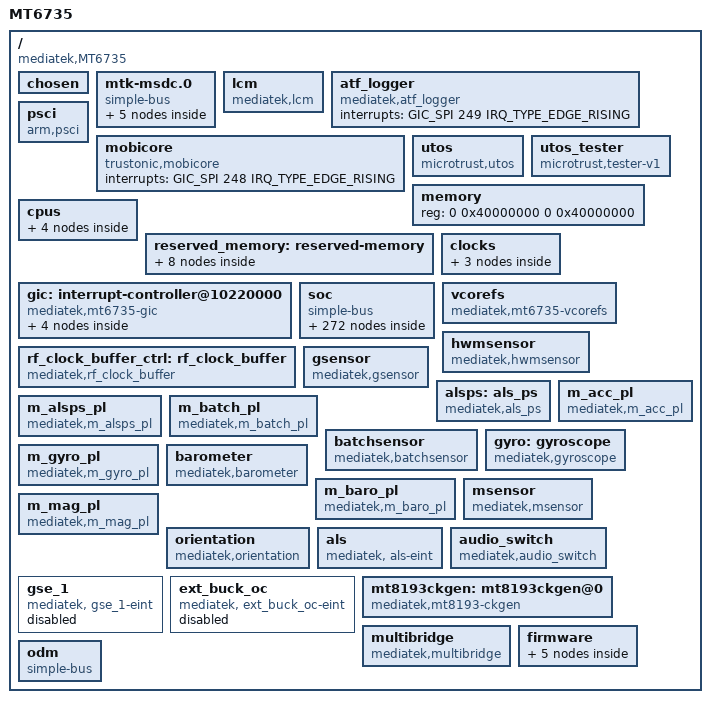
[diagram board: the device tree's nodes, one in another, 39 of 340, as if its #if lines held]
/*
 * Copyright (c) 2015 MediaTek Inc.
 *
 * This program is free software; you can redistribute it and/or modify
 * it under the terms of the GNU General Public License version 2 as
 * published by the Free Software Foundation.
 *
 * This program is distributed in the hope that it will be useful,
 * but WITHOUT ANY WARRANTY; without even the implied warranty of
 * MERCHANTABILITY or FITNESS FOR A PARTICULAR PURPOSE.  See the
 * GNU General Public License for more details.
 */

#include <generated/autoconf.h>
#include <dt-bindings/clock/mt6735-clk.h>
#include <dt-bindings/interrupt-controller/arm-gic.h>
#include <dt-bindings/interrupt-controller/irq.h>
#include "mt6735-pinfunc.h"
#include <dt-bindings/mmc/mt67xx-msdc.h>
#ifdef CONFIG_MTK_DTBO_FEATURE
/dts-v1/;
#endif

/ {
	model = "MT6735";
	compatible = "mediatek,MT6735";
	interrupt-parent = <&gic>;
	#address-cells = <2>;
	#size-cells = <2>;

	/* chosen */
	chosen: chosen {
		bootargs = "console=tty0 console=ttyMT3,921600n1 vmalloc=496M \
androidboot.hardware=mt6735 slub_max_order=0 slub_debug=OFZPU \
firmware_class.path=/vendor/firmware";
	};

	/* Do not put any bus before mtk-msdc, because it should be mtk-msdc.0 for partition device node usage */
	/*workaround for .0*/
	mtk-msdc.0 {
		compatible = "simple-bus";
		#address-cells = <1>;
		#size-cells = <1>;
		ranges = <0 0 0 0xffffffff>;

		mmc0: msdc0@11230000{
				compatible = "mediatek,mt6735-mmc";
				reg = <0x11230000 0x10000  /* MSDC0_BASE   */
					0x10000e84 0x2>;    /* FPGA PWR_GPIO, PWR_GPIO_EO */
				interrupts = <GIC_SPI 79 IRQ_TYPE_LEVEL_LOW>;
				status = "disabled";
				clocks = <&perisys PERI_MSDC30_0>,
					 <&topckgen TOP_MUX_MSDC30_0>,
					 <&topckgen TOP_MSDCPLL_CK>,
					 <&topckgen TOP_MSDCPLL_D2>,
					 <&topckgen TOP_MSDCPLL_D4>;
				clock-names="MSDC0-CLOCK",
					"MSDC0_PLL_SEL",
					"MSDC0_PLL_800M",
					"MSDC0_PLL_400M",
					"MSDC0_PLL_200M";
		};

		mmc1: msdc1@11240000{
				compatible = "mediatek,mt6735-mmc";
				reg = <0x11240000 0x10000  /* MSDC1_BASE   */
					0x10000e84 0x2>;    /* FPGA PWR_GPIO, PWR_GPIO_EO */
				interrupts = <GIC_SPI 80 IRQ_TYPE_LEVEL_LOW>;
				status = "disabled";
				clocks = <&perisys PERI_MSDC30_1>;
				clock-names="MSDC1-CLOCK";
		};

		mmc2: msdc2@11250000{
				compatible = "mediatek,mt6735-mmc";
				reg = <0x11250000 0x10000  /* MSDC2_BASE   */
					0x10000e84 0x2>;    /* FPGA PWR_GPIO, PWR_GPIO_EO */
				interrupts = <GIC_SPI 81 IRQ_TYPE_LEVEL_LOW>;
				status = "disabled";
				clocks = <&perisys PERI_MSDC30_2>;
				clock-names="MSDC2-CLOCK";
		};

		mmc3: msdc3@11260000{
				compatible = "mediatek,mt6735-mmc";
				reg = <0x11260000 0x10000  /* MSDC2_BASE   */
					0x10000e84 0x2>;    /* FPGA PWR_GPIO, PWR_GPIO_EO */
				interrupts = <GIC_SPI 82 IRQ_TYPE_LEVEL_LOW>;
				status = "disabled";
				clocks = <&perisys PERI_MSDC30_3>;
				clock-names="MSDC3-CLOCK";
		};

	/* only used for old way of DCT, can be removed in new platform */
	msdc1_ins: default {
		compatible = "mediatek, msdc1_ins-eint";
	};
	};
	lcm: lcm {
		compatible = "mediatek,lcm";
	};

	/* ATF logger SW IRQ number 281 = 32 + 249 */
	atf_logger {
		compatible = "mediatek,atf_logger";
		interrupts = <GIC_SPI 249 IRQ_TYPE_EDGE_RISING>;
	};

	psci {
		compatible  = "arm,psci";
		method      = "smc";
		cpu_suspend = <0x84000001>;
		cpu_off     = <0x84000002>;
		cpu_on      = <0x84000003>;
		affinity_info = <0x84000004>;
	};

	mobicore {
		compatible = "trustonic,mobicore";
		interrupts = <GIC_SPI 248 IRQ_TYPE_EDGE_RISING>;
	};

	utos {
	compatible = "microtrust,utos";
	interrupts = <GIC_SPI 252 IRQ_TYPE_EDGE_RISING>,
		<GIC_SPI 253 IRQ_TYPE_EDGE_RISING>;
	};
	utos_tester {
		compatible = "microtrust,tester-v1";
	};


	memory {
		device_type = "memory";
		reg = <0 0x40000000 0 0x40000000>;
	};

	cpus: cpus {
		#address-cells = <1>;
		#size-cells = <0>;

		cpu0: cpu@000 {
			device_type = "cpu";
			compatible = "arm,cortex-a53";
			reg = <0x000>;
			enable-method = "spin-table";
			cpu-release-addr = <0x0 0x40000200>;
			clock-frequency = <1300000000>;
		};

		cpu1: cpu@001 {
			device_type = "cpu";
			compatible = "arm,cortex-a53";
			reg = <0x001>;
			enable-method = "spin-table";
			cpu-release-addr = <0x0 0x40000200>;
			clock-frequency = <1300000000>;
		};

		cpu2: cpu@002 {
			device_type = "cpu";
			compatible = "arm,cortex-a53";
			reg = <0x002>;
			enable-method = "spin-table";
			cpu-release-addr = <0x0 0x40000200>;
			clock-frequency = <1300000000>;
		};

		cpu3: cpu@003 {
			device_type = "cpu";
			compatible = "arm,cortex-a53";
			reg = <0x003>;
			enable-method = "spin-table";
			cpu-release-addr = <0x0 0x40000200>;
			clock-frequency = <1300000000>;
		};
	};

	reserved_memory: reserved-memory {
		#address-cells = <2>;
		#size-cells = <2>;
		ranges;

		atf-reserved-memory@43000000 {
			compatible = "mediatek,mt6735-atf-reserved-memory",
				     "mediatek,mt6735m-atf-reserved-memory",
				     "mediatek,mt6753-atf-reserved-memory";
			no-map;
			reg = <0 0x43000000 0 0x30000>;
		};

		ram_console-reserved-memory@43f00000{
			compatible = "mediatek,ram_console";
			reg = <0 0x43f00000 0 0x10000>;
		};

		pstore-reserved-memory@43f10000 {
			compatible = "mediatek,pstore";
			reg = <0 0x43f10000 0 0xe0000>;
		};

		minirdump-reserved-memory@43ff0000{
			compatible = "mediatek,minirdump";
			reg = <0 0x43ff0000 0 0x10000>;
		};

		reserve-memory-ccci_md1 {
			compatible = "mediatek,reserve-memory-ccci_md1";
			no-map;
			size = <0 0x3810000>; /* md_size+smem_size */
			alignment = <0 0x2000000>;
			alloc-ranges = <0 0x40000000 0 0xC0000000>;
		};

		consys-reserve-memory {
			compatible = "mediatek,consys-reserve-memory";
			no-map;
			size = <0 0x100000>;
			alignment = <0 0x200000>;
		};

#ifdef CONFIG_MICROTRUST_TEE_SUPPORT
		soter-shared-mem {
			compatible = "microtrust,shared_mem";
			no-map;
			size = <0 0x200000>;
			alloc-ranges = <0 0x40000000 0 0x50000000>;
		};
#endif

		spm-reserve-memory {
			compatible = "mediatek,spm-reserve-memory";
			no-map;
			size = <0 0x10000>; /* PCM_FIRMWARE_SIZE * DYNA_LOAD_PCM_MAX = 4K * 4 */
			alignment = <0 0x10000>;
			alloc-ranges = <0 0x40000000 0 0x60000000>;
		};
	};

	gic: interrupt-controller@10220000 {
		compatible = "mediatek,mt6735-gic";
		#interrupt-cells = <3>;
		#address-cells = <0>;
		interrupt-controller;
		reg =	<0 0x10221000 0 0x1000>,
			<0 0x10222000 0 0x1000>,
			<0 0x10200620 0 0x1000>;

		mediatek,wdt_irq = <160>;

		gic-cpuif@0 {
			compatible = "arm,gic-cpuif";
			cpuif-id = <0>;
			cpu = <&cpu0>;
		};

		gic-cpuif@1 {
			compatible = "arm,gic-cpuif";
			cpuif-id = <1>;
			cpu = <&cpu1>;
		};

		gic-cpuif@2 {
			compatible = "arm,gic-cpuif";
			cpuif-id = <2>;
			cpu = <&cpu2>;
		};

		gic-cpuif@3 {
			compatible = "arm,gic-cpuif";
			cpuif-id = <3>;
			cpu = <&cpu3>;
		};
	};

	clocks {
		clk_null: clk_null {
			compatible = "fixed-clock";
			#clock-cells = <0>;
			clock-frequency = <0>;
		};

		clk26m: clk26m {
			compatible = "fixed-clock";
			#clock-cells = <0>;
			clock-frequency = <26000000>;
		};

		clk32k: clk32k {
			compatible = "fixed-clock";
			#clock-cells = <0>;
			clock-frequency = <32000>;
		};
	};

	soc: soc {
		compatible = "simple-bus";
		#address-cells = <1>;
		#size-cells = <1>;
		ranges = <0 0 0 0xffffffff>;


		topckgen: topckgen@10210000 {
			compatible = "mediatek,mt6735-topckgen";
			reg = <0x10210000 0x1000>;
			#clock-cells = <1>;
		};


		chipid@08000000 {
			compatible = "mediatek,chipid";
			reg =	<0x08000000 0x0004>,
				<0x08000004 0x0004>,
				<0x08000008 0x0004>,
				<0x0800000C 0x0004>;
		};

		infrasys: infrasys@10000000 {
			compatible = "mediatek,mt6735-infrasys";
			reg = <0x10000000 0x1000>;
			#clock-cells = <1>;
		};

		scpsys: scpsys@10000000 {
			compatible = "mediatek,mt6735-scpsys";
			reg = <0x10000000 0x1000>, <0x10006000 0x1000>;
			#clock-cells = <1>;
		};


		infracfg_ao@10000000 {
			compatible = "mediatek,infracfg_ao";
			reg = <0x10000000 0x1000>;
		};

		usb2jtag: usb2jtag@10000000 {
			compatible = "mediatek,usb2jtag_v1";
			reg = <0x10000000 0x1000>, <0x11210000 0x1000>;
		};

		pwrap@10001000 {
			compatible = "mediatek,PWRAP";
			reg = <0x10001000 0x1000>;
			interrupts = <GIC_SPI 163 IRQ_TYPE_LEVEL_HIGH>;
		};

		perisys: perisys@10002000 {
			compatible = "mediatek,mt6735-perisys";
			reg = <0x10002000 0x1000>;
			#clock-cells = <1>;
		};

		hacc@10008000 {
			compatible = "mediatek,hacc";
			reg = <0x10008000 0x1000>;
			interrupts = <GIC_SPI 174 IRQ_TYPE_LEVEL_LOW>;
		};

		pericfg@10002000 {
			compatible = "mediatek,pericfg";
			reg = <0x10002000 0x1000>;
		};


		keypad: keypad@10003000 {
			compatible = "mediatek,mt6735-keypad";
			reg = <0x10003000 0x1000>;
			interrupts = <GIC_SPI 164 IRQ_TYPE_EDGE_FALLING>;
		};

		apxgpt: apxgpt@10004000 {
			compatible = "mediatek,mt6735-apxgpt";
			reg = <0x10004000 0x1000>;
			interrupts = <GIC_SPI 152 IRQ_TYPE_LEVEL_LOW>;
			clock-frequency = <13000000>;
		};

		eintc: eintc@10005000 {
			compatible = "mediatek,mt-eic";
			reg = <0x10005000 0x1000>;
			interrupts = <GIC_SPI 153 IRQ_TYPE_LEVEL_HIGH>;

			#interrupt-cells = <2>;
			interrupt-controller;

			mediatek,max_eint_num = <213>;
			mediatek,mapping_table_entry = <0>;

			mediatek,debtime_setting_entry = <10>;
			mediatek,debtime_setting_array	= <0 125>,
							<1 250>,
							<2 500>,
							<3 1000>,
							<4 16000>,
							<5 32000>,
							<6 64000>,
							<7 128000>,
							<8 256000>,
							<9 512000>;
		};

		sleep@10006000 {
			compatible = "mediatek,sleep";
			reg = <0x10006000 0x1000>;
			interrupts = <0 165 0x8>,
				     <0 166 0x8>,
				     <0 167 0x8>,
				     <0 168 0x8>;
		};

		mdcldma:mdcldma@1000A000 {
			compatible = "mediatek,mdcldma";
			reg =	<0x1000A000 0x1000>, /*AP_CLDMA_AO*/
				<0x1000B000 0x1000>, /*MD_CLDMA_AO*/
				<0x1021A000 0x1000>, /*AP_CLDMA_PDN*/
				<0x1021B000 0x1000>, /*MD_CLDMA_PDN*/
				<0x1020A000 0x1000>, /*AP_CCIF_BASE*/
				<0x1020B000 0x1000>; /*MD_CCIF_BASE*/
			interrupts =	<GIC_SPI 145 IRQ_TYPE_LEVEL_HIGH>, /*IRQ_CLDMA*/
					<GIC_SPI 140 IRQ_TYPE_LEVEL_LOW>, /*IRQ_CCIF*/
					<GIC_SPI 221 IRQ_TYPE_EDGE_FALLING>; /*IRQ_MDWDT*/
			mediatek,md_id = <0>;
			mediatek,cldma_capability = <6>;
			mediatek,md_smem_size = <0x10000>; /* md share memory size */
			clocks = <&scpsys SCP_SYS_MD1>;
			clock-names = "scp-sys-md1-main";
		};

		mcucfg@10200000 {
			compatible = "mediatek,mcucfg";
			reg = <0x10200000 0x200>;
			interrupts = <GIC_SPI 71 IRQ_TYPE_LEVEL_HIGH>;
		};

		cpuxgpt: cpuxgpt@10200000 {
			compatible = "mediatek,mt6735-cpuxgpt";
			reg = <0x10200000 0x1000>;
			interrupts = <GIC_SPI 64 IRQ_TYPE_LEVEL_HIGH>,
				<GIC_SPI 65 IRQ_TYPE_LEVEL_HIGH>,
				<GIC_SPI 66 IRQ_TYPE_LEVEL_HIGH>,
				<GIC_SPI 67 IRQ_TYPE_LEVEL_HIGH>,
				<GIC_SPI 68 IRQ_TYPE_LEVEL_HIGH>,
				<GIC_SPI 69 IRQ_TYPE_LEVEL_HIGH>,
				<GIC_SPI 70 IRQ_TYPE_LEVEL_HIGH>,
				<GIC_SPI 71 IRQ_TYPE_LEVEL_HIGH>;
		};

		lastpc: lastpc@10200000 {
			compatible = "mediatek,mt6735-mcucfg";
			reg = <0x10200000 0x200>;
			interrupts = <GIC_SPI 71 IRQ_TYPE_LEVEL_HIGH>;
		};

		emi@10203000 {
			compatible = "mediatek,emi";
			reg = <0x10203000 0x1000>;
			interrupts = <GIC_SPI 136 IRQ_TYPE_LEVEL_HIGH>;
		};


		sys_cirq: sys_cirq@10204000 {
			compatible = "mediatek,mt6735-sys_cirq";
			reg = <0x10204000 0x1000>;
			interrupts = <GIC_SPI 231 IRQ_TYPE_LEVEL_LOW>;
			mediatek,cirq_num = <159>;
			mediatek,spi_start_offset = <72>;
		};

		m4u@10205000 {
			cell-index = <0>;
			compatible = "mediatek,m4u";
			reg = <0x10205000 0x1000>;
			interrupts = <GIC_SPI 146 IRQ_TYPE_LEVEL_LOW>;
			clocks = <&infrasys INFRA_M4U>,
				<&mmsys MM_DISP0_SMI_COMMON>,
				<&mmsys MM_DISP0_SMI_LARB0>,
				<&vdecsys VDEC0_VDEC>,
				<&vdecsys VDEC1_LARB>,
				<&imgsys IMG_IMAGE_LARB2_SMI>,
				<&vencsys VENC_VENC>,
				<&vencsys VENC_LARB>,
				<&scpsys SCP_SYS_DIS>,
				<&scpsys SCP_SYS_VDE>,
				<&scpsys SCP_SYS_ISP>,
				<&scpsys SCP_SYS_VEN>;
			clock-names = "infra_m4u",
					"smi_common",
					"m4u_disp0_smi_larb0",
					"m4u_vdec0_vdec",
					"m4u_vdec1_larb",
					"m4u_img_image_larb2_smi",
					"m4u_venc_venc",
					"m4u_venc_larb",
					"mtcmos-dis",
					"mtcmos-vde",
					"mtcmos-isp",
					"mtcmos-ven";
		};

		efusec@10206000 {
			compatible = "mediatek,efusec";
			reg = <0x10206000 0x1000>;
		};

		devapc@10207000 {
			compatible = "mediatek,devapc";
			reg = <0x10207000 0x1000>;
			interrupts = <GIC_SPI 134 IRQ_TYPE_LEVEL_LOW>;
			clocks = <&infrasys INFRA_DEVAPC>;
			clock-names = "devapc-main";
		};

		bus_dbg@10208000 {
			compatible = "mediatek,bus_dbg-v1";
			reg = <0x10208000 0x1000>;
			interrupts = <GIC_SPI 137 IRQ_TYPE_LEVEL_LOW>;
		};

		apmixedsys: apmixedsys@10209000 {
			compatible = "mediatek,mt6735-apmixedsys";
			reg = <0x10209000 0x1000>;
			#clock-cells = <1>;
		};

		apmixed@10209000 {
			compatible = "mediatek,apmixed";
			reg = <0x10209000 0x1000>;
		};

		fhctl@10209f00 {
			compatible = "mediatek,fhctl";
			reg = <0x10209f00 0x100>;
		};

		dramc_nao: dramc_nao@1020e000 {
			compatible = "mediatek,mt6735-dramc_nao";
			reg = <0x1020e000 0x1000>;
		};



		cksys@10210000 {
			compatible = "mediatek,cksys";
			reg = <0x10210000 0x1000>;
		};

		syscfg_pctl_a: syscfg_pctl_a@10211000 {
			compatible = "mediatek,mt6735-pctl-a-syscfg", "syscon";
			reg = <0 10211000 0 1000>;
		};

		pio: pinctrl@10211000 {
			compatible = "mediatek,mt6735-pinctrl";
			reg = <0 10211000 0 1000>;
			mediatek,pctl-regmap = <&syscfg_pctl_a>;
			pins-are-numbered;
			gpio-controller;
			#gpio-cells = <2>;
		};

		gpio_usage_mapping:gpio {
			compatible = "mediatek,gpio_usage_mapping";
		};

		gpio: gpio@10211000 {
			compatible = "mediatek,gpio";
			reg = <0x10211000 0x1000>;
		};

		toprgu: toprgu@10212000 {
			compatible = "mediatek,mt6735-rgu";
			reg = <0x10212000 0x1000>;
			interrupts = <GIC_SPI 128 IRQ_TYPE_EDGE_FALLING>;
		};

		ddrphy: ddrphy@10213000 {
			compatible = "mediatek,mt6735-ddrphy";
			reg = <0x10213000 0x1000>;
		};

		dramc: dramc@10214000 {
			compatible = "mediatek,mt6735-dramc";
			reg = <0x10214000 0x1000>;
			clocks = <&infrasys INFRA_GCE>;
			clock-names = "infra-cqdma";
		};

		gcpu@10216000 {
			compatible = "mediatek,gcpu";
			reg = <0x10216000 0x1000>;
			interrupts = <GIC_SPI 150 IRQ_TYPE_LEVEL_LOW>;
		};

		gce@10217000 {
			compatible = "mediatek,gce";
			reg = <0x10217000 0x1000>;
			interrupts = <GIC_SPI 151 IRQ_TYPE_LEVEL_LOW>,
						<GIC_SPI 148 IRQ_TYPE_LEVEL_LOW>;
			disp_mutex_reg = <0x14014000 0x1000>;
			g3d_config_base = <0x13000000 0 0xffff0000>;
			mmsys_config_base = <0x14000000 1 0xffff0000>;
			disp_dither_base = <0x14010000 2 0xffff0000>;
			mm_na_base = <0x14020000 3 0xffff0000>;
			imgsys_base = <0x15000000 4 0xffff0000>;
			vdec_gcon_base = <0x16000000 5 0xffff0000>;
			venc_gcon_base = <0x17000000 6 0xffff0000>;
			conn_peri_base = <0x18000000 7 0xffff0000>;
			topckgen_base = <0x10000000 8 0xffff0000>;
			kp_base = <0x10010000 9 0xffff0000>;
			scp_sram_base = <0x10020000 10 0xffff0000>;
			infra_na3_base = <0x10030000 11 0xffff0000>;
			infra_na4_base = <0x10040000 12 0xffff0000>;
			scp_base = <0x10050000 13 0xffff0000>;
			mcucfg_base = <0x10200000 14 0xffff0000>;
			gcpu_base = <0x10210000 15 0xffff0000>;
			usb0_base = <0x11200000 16 0xffff0000>;
			usb_sif_base = <0x11210000 17 0xffff0000>;
			audio_base = <0x11220000 18 0xffff0000>;
			msdc0_base = <0x11230000 19 0xffff0000>;
			msdc1_base = <0x11240000 20 0xffff0000>;
			msdc2_base = <0x11250000 21 0xffff0000>;
			msdc3_base = <0x11260000 22 0xffff0000>;
			pwm_sw_base = <0x1100E000 99 0xfffff000>;
			mdp_rdma0_sof = <0>;
			mdp_rsz0_sof = <1>;
			mdp_rsz1_sof = <2>;
			dsi0_te_event = <3>;
			mdp_wdma_sof = <4>;
			mdp_wrot_sof = <5>;
			disp_ovl0_sof = <6>;
			disp_rdma0_sof = <7>;
			disp_rdma1_sof = <8>;
			disp_wdma0_sof = <9>;
			disp_ccorr_sof = <10>;
			disp_color_sof = <11>;
			disp_aal_sof = <12>;
			disp_gamma_sof = <13>;
			disp_dither_sof = <14>;
			disp_pwm0_sof = <16>;
			mdp_rdma0_frame_done = <17>;
			mdp_rsz0_frame_done = <18>;
			mdp_rsz1_frame_done = <19>;
			mdp_tdshp_frame_done = <20>;
			mdp_wdma_frame_done = <21>;
			mdp_wrot_write_frame_done = <22>;
			mdp_wrot_read_frame_done = <23>;
			disp_ovl0_frame_done = <24>;
			disp_rdma0_frame_done = <25>;
			disp_rdma1_frame_done = <26>;
			disp_wdma0_frame_done = <27>;
			disp_ccorr_frame_done = <28>;
			disp_color_frame_done = <29>;
			disp_aal_frame_done = <30>;
			disp_gamma_frame_done = <31>;
			disp_dither_frame_done = <32>;
			disp_dpi0_frame_done = <34>;
			stream_done_0 = <35>;
			stream_done_1 = <36>;
			stream_done_2 = <37>;
			stream_done_3 = <38>;
			stream_done_4 = <39>;
			stream_done_5 = <40>;
			stream_done_6 = <41>;
			stream_done_7 = <42>;
			stream_done_8 = <43>;
			stream_done_9 = <44>;
			buf_underrun_event_0 = <45>;
			buf_underrun_event_1 = <46>;
			mdp_tdshp_sof = <47>;
			isp_frame_done_p2_2 = <65>;
			isp_frame_done_p2_1 = <66>;
			isp_frame_done_p2_0 = <67>;
			isp_frame_done_p1_1 = <68>;
			isp_frame_done_p1_0 = <69>;
			camsv_2_pass1_done = <70>;
			camsv_1_pass1_done = <71>;
			seninf_cam1_2_3_fifo_full = <72>;
			seninf_cam0_fifo_full = <73>;
			venc_done = <129>;
			jpgenc_done = <130>;
			jpgdec_done = <131>;
			venc_mb_done = <132>;
			venc_128byte_cnt_done = <133>;
			apxgpt2_count = <0x10004028>;
			clocks = <&infrasys INFRA_GCE>;
			clock-names = "GCE";
		};

		cqdma@10217c00 {
			compatible = "mediatek,cqdma";
			reg = <0x10217c00 0xc00>;
			interrupts = <GIC_SPI 151 IRQ_TYPE_LEVEL_LOW>;
			nr_channel = <1>;
		};

		mcu_biu: mcu_biu@10300000 {
			compatible = "mediatek,mt6735-mcu_biu";
			reg = <0x10300000 0x8000>;
		};

		cpu_dbgapb: cpu_dbgapb@10810000 {
			compatible = "mediatek,hw_dbg";
			num = <4>;
			reg =  <0x10810000 0x1000
				0x10910000 0x1000
				0x10a10000 0x1000
				0x10b10000 0x1000>;
		};

		auxadc: adc_hw@11001000 {
			compatible = "mediatek,mt6735-auxadc";
			reg = <0x11001000 0x1000>;
			interrupts = <GIC_SPI 76 IRQ_TYPE_EDGE_FALLING>;
			clocks = <&perisys PERI_AUXADC>;
			clock-names = "auxadc-main";
		};

		dbgapb_base@1011a000{
			compatible = "mediatek,dbgapb_base";
			reg = <0x1011a000 0x100>;/* MD debug register */
		};

		ap_dma:dma@11000000 {
			compatible = "mediatek,ap_dma";
			reg = <0x11000000 0x1000>;
			interrupts = <GIC_SPI 114 IRQ_TYPE_LEVEL_LOW>;
		};

		btif_tx: btif_tx@11000880 {
			compatible = "mediatek,btif_tx";
			reg = <0x11000880 0x80>;
			interrupts = <GIC_SPI 113 IRQ_TYPE_LEVEL_LOW>;
		};

		btif_rx: btif_rx@11000900 {
			compatible = "mediatek,btif_rx";
			reg = <0x11000900 0x80>;
			interrupts = <GIC_SPI 114 IRQ_TYPE_LEVEL_LOW>;
		};

		apirtx:irtx@11011000 {
			compatible = "mediatek,irtx";
			reg = <0x11011000 0x1000>;
			interrupts = <GIC_SPI 124 IRQ_TYPE_LEVEL_HIGH>;
			pwm_ch = <0>;

			clock-frequency = <26000000>;
			clock-div = <1>;
			clocks = <&perisys PERI_IRTX>;
			clock-names = "clk-irtx-main";

			pinctrl-names = "irtx_gpio_default",
					"irtx_gpio_led_set";

			pinctrl-0 = <&irtx_gpio_default>;
			pinctrl-1 = <&irtx_gpio_led_set>;
			status = "okay";
		};

		irtx-pwm {
			compatible = "mediatek,irtx-pwm";
			pwm_ch = <2>;
			pwm_data_invert = <0>;
		};

		irlearning:irlearning-spi {
			compatible = "mediatek,irlearning-spi";
			spi_clock = <109000000>;
			spi_data_invert = <0>;
			spi_cs_invert = <1>;
		};

		apuart0: apuart0@11002000 {
			cell-index = <0>;
			compatible = "mediatek,mt6735-uart";
			reg =	<0x11002000 0x1000>, /* UART base */
				<0x11000380 0x1000>, /* DMA Tx base */
				<0x11000400 0x80>; /* DMA Rx base */
			interrupts =	<GIC_SPI 91 IRQ_TYPE_LEVEL_LOW>, /* UART IRQ */
					<GIC_SPI 103 IRQ_TYPE_LEVEL_LOW>, /* DMA Tx IRQ */
					<GIC_SPI 104 IRQ_TYPE_LEVEL_LOW>; /* DMA Rx IRQ */

			clock-frequency = <26000000>;
			clock-div = <1>;
			clocks = <&perisys PERI_UART0>, <&perisys PERI_APDMA>;
			clock-names = "uart0-main", "uart-apdma";

			pinctrl-names = "uart0_gpio_default",
					"uart0_rx_set",
					"uart0_rx_clear",
					"uart0_tx_set",
					"uart0_tx_clear";

			pinctrl-0 = <&uart0_gpio_def_cfg>;
			pinctrl-1 = <&uart0_rx_set_cfg>;
			pinctrl-2 = <&uart0_rx_clr_cfg>;
			pinctrl-3 = <&uart0_tx_set_cfg>;
			pinctrl-4 = <&uart0_tx_clr_cfg>;
			status = "okay";
		};

		apuart1: apuart1@11003000 {
			cell-index = <1>;
			compatible = "mediatek,mt6735-uart";
			reg =	<0x11003000 0x1000>, /* UART base */
				<0x11000480 0x80>, /* DMA Tx base */
				<0x11000500 0x80>; /* DMA Rx base */
			interrupts = <GIC_SPI 92 IRQ_TYPE_LEVEL_LOW>, /* UART IRQ */
						 <GIC_SPI 105 IRQ_TYPE_LEVEL_LOW>, /* DMA Tx IRQ */
						 <GIC_SPI 106 IRQ_TYPE_LEVEL_LOW>; /* DMA Rx IRQ */

			clock-frequency = <26000000>;
			clock-div = <1>;
			clocks = <&perisys PERI_UART1>;
			clock-names = "uart1-main";

			pinctrl-names = "uart1_gpio_default",
					"uart1_rx_set",
					"uart1_rx_clear",
					"uart1_tx_set",
					"uart1_tx_clear";

			pinctrl-0 = <&uart1_gpio_def_cfg>;
			pinctrl-1 = <&uart1_rx_set_cfg>;
			pinctrl-2 = <&uart1_rx_clr_cfg>;
			pinctrl-3 = <&uart1_tx_set_cfg>;
			pinctrl-4 = <&uart1_tx_clr_cfg>;
			status = "okay";
		};

		apuart2: apuart2@11004000 {
			cell-index = <2>;
			compatible = "mediatek,mt6735-uart";
			reg =	<0x11004000 0x1000>, /* UART base */
				<0x11000580 0x80>, /* DMA Tx base */
				<0x11000600 0x80>; /* DMA Rx base */
			interrupts = <GIC_SPI 93 IRQ_TYPE_LEVEL_LOW>, /* UART IRQ */
						 <GIC_SPI 107 IRQ_TYPE_LEVEL_LOW>, /* DMA Tx IRQ */
						 <GIC_SPI 108 IRQ_TYPE_LEVEL_LOW>; /* DMA Rx IRQ */

			clock-frequency = <26000000>;
			clock-div = <1>;
			clocks = <&perisys PERI_UART2>;
			clock-names = "uart2-main";

			pinctrl-names = "uart2_gpio_default",
					"uart2_rx_set",
					"uart2_rx_clear",
					"uart2_tx_set",
					"uart2_tx_clear";

			pinctrl-0 = <&uart2_gpio_def_cfg>;
			pinctrl-1 = <&uart2_rx_set_cfg>;
			pinctrl-2 = <&uart2_rx_clr_cfg>;
			pinctrl-3 = <&uart2_tx_set_cfg>;
			pinctrl-4 = <&uart2_tx_clr_cfg>;
			status = "okay";
		};

		apuart3: apuart3@11005000 {
			cell-index = <3>;
			compatible = "mediatek,mt6735-uart";
			reg =	<0x11005000 0x1000>, /* UART base */
				<0x11000680 0x80>, /* DMA Tx base */
				<0x11000700 0x80>; /* DMA Rx base */
			interrupts = <GIC_SPI 94 IRQ_TYPE_LEVEL_LOW>, /* UART IRQ */
						 <GIC_SPI 109 IRQ_TYPE_LEVEL_LOW>, /* DMA Tx IRQ */
						 <GIC_SPI 110 IRQ_TYPE_LEVEL_LOW>; /* DMA Rx IRQ */

			clock-frequency = <26000000>;
			clock-div = <1>;
			clocks = <&perisys PERI_UART3>;
			clock-names = "uart3-main";

			pinctrl-names = "uart3_gpio_default",
					"uart3_rx_set",
					"uart3_rx_clear",
					"uart3_tx_set",
					"uart3_tx_clear";

			pinctrl-0 = <&uart3_gpio_def_cfg>;
			pinctrl-1 = <&uart3_rx_set_cfg>;
			pinctrl-2 = <&uart3_rx_clr_cfg>;
			pinctrl-3 = <&uart3_tx_set_cfg>;
			pinctrl-4 = <&uart3_tx_clr_cfg>;
			status = "okay";
		};

		pwm:pwm@11006000 {
			compatible = "mediatek,pwm";
			reg = <0x11006000 0x1000>;
			interrupts = <GIC_SPI 77 IRQ_TYPE_LEVEL_LOW>;
			clocks = <&perisys PERI_PWM>,
					 <&perisys PERI_PWM1>,
					 <&perisys PERI_PWM2>,
					 <&perisys PERI_PWM3>,
					 <&perisys PERI_PWM4>,
					 <&perisys PERI_PWM5>;
			clock-names =	"PWM-main",
					"PWM1-main",
					"PWM2-main",
					"PWM3-main",
					"PWM4-main",
					"PWM5-main";
		};

		devapc_ao@10007000 {
			compatible = "mediatek,devapc_ao";
			reg = <0x10007000 0x1000>;
		};

		i2c0:i2c@11007000 {
			compatible = "mediatek,mt6735-i2c";
			cell-index = <0>;
			reg = <0x11007000 0x1000>;
			interrupts =	<GIC_SPI 84 IRQ_TYPE_LEVEL_LOW>,
					<GIC_SPI 99 IRQ_TYPE_LEVEL_LOW>;
			def_speed = <100>;
			clocks = <&perisys PERI_I2C0>, <&perisys PERI_APDMA>;
			clock-names = "i2c0-main", "i2c0-dma";
			clock-frequency = <13600>;
			clock-div = <1>;
		};

		i2c1:i2c@11008000 {
			compatible = "mediatek,mt6735-i2c";
			cell-index = <1>;
			reg = <0x11008000 0x1000>;
			interrupts =	<GIC_SPI 85 IRQ_TYPE_LEVEL_LOW>,
					<GIC_SPI 100 IRQ_TYPE_LEVEL_LOW>;
			def_speed = <100>;
			clocks = <&perisys PERI_I2C1>, <&perisys PERI_APDMA>;
			clock-names = "i2c1-main", "i2c1-dma";
			clock-frequency = <13600>;
			clock-div = <1>;
		};
		spi0:spi@1100a000 {
			compatible = "mediatek,mt6735-spi";
			cell-index = <0>;
			spi-padmacro = <0>;
			reg = <0x1100a000 0x1000>;
			interrupts = <GIC_SPI 118 IRQ_TYPE_LEVEL_LOW>;
			clocks = <&perisys PERI_SPI0>;
			clock-names = "spi-main";
			clock-frequency = <109000000>;
			clock-div = <1>;
		};

		i2c2:i2c@11009000 {
			compatible = "mediatek,mt6735-i2c";
			cell-index = <2>;
			reg = <0x11009000 0x1000>;
			interrupts =	<GIC_SPI 86 IRQ_TYPE_LEVEL_LOW>,
					<GIC_SPI 101 IRQ_TYPE_LEVEL_LOW>;
			def_speed = <100>;
			clocks = <&perisys PERI_I2C2>, <&perisys PERI_APDMA>;
			clock-names = "i2c2-main", "i2c2-dma";
			clock-frequency = <13600>;
			clock-div = <1>;
		};

		therm_ctrl@1100b000 {
			compatible = "mediatek,mt6735-therm_ctrl";
			reg = <0x1100b000 0x1000>;
			interrupts = <GIC_SPI 78 IRQ_TYPE_LEVEL_LOW>;
			clocks = <&perisys PERI_THERM>;
			clock-names = "therm-main";
		};


		ptp_fsm@1100b000 {
			compatible = "mediatek,ptp_fsm_v1";
			reg = <0x1100b000 0x1000>;
			interrupts = <GIC_SPI 125 IRQ_TYPE_LEVEL_LOW>;
		};

		btif: btif@1100c000 {
			compatible = "mediatek,btif";
			reg = <0x1100c000 0x1000>;
			interrupts = <GIC_SPI 90 IRQ_TYPE_LEVEL_LOW>;
			clocks = <&perisys PERI_BTIF>,<&perisys PERI_APDMA>;
			clock-names = "btifc","apdmac";
		};/* End of btif */

		apuart4: apuart4@1100D000 {
			cell-index = <4>;
			compatible = "mediatek,mt6735-uart";
			reg =	<0x1100d000 0x1000>, /* UART base */
				<0x11000780 0x80>, /* DMA Tx base */
				<0x11000800 0x80>; /* DMA Rx base */
			interrupts =	<GIC_SPI 95 IRQ_TYPE_LEVEL_LOW>, /* UART IRQ */
					<GIC_SPI 111 IRQ_TYPE_LEVEL_LOW>, /* DMA Tx IRQ */
					<GIC_SPI 112 IRQ_TYPE_LEVEL_LOW>; /* DMA Rx IRQ */

			clock-frequency = <26000000>;
			clock-div = <1>;
			clocks = <&perisys PERI_UART4>;
			clock-names = "uart4-main";
		};

		i2c3:i2c@1100f000 {
			compatible = "mediatek,mt6735-i2c";
			cell-index = <3>;
			reg = <0x1100f000 0x1000>;
			interrupts =	<GIC_SPI 87 IRQ_TYPE_LEVEL_LOW>,
					<GIC_SPI 102 IRQ_TYPE_LEVEL_LOW>;
			def_speed = <100>;
			clocks = <&perisys PERI_I2C3>, <&perisys PERI_APDMA>;
			clock-names = "i2c3-main", "i2c3-dma";
			clock-frequency = <13600>;
			clock-div = <1>;
		};

		i2c4:i2c@11010000 {
			compatible = "mediatek,mt6735-i2c";
			cell-index = <4>;
			reg = <11010000 0x1000>;
			def_speed = <100>;
			clocks = <&perisys PERI_I2C3>, <&perisys PERI_APDMA>;
			clock-names = "i2c4-main", "i2c4-dma";
			clock-frequency = <13600>;
			clock-div = <1>;
		};

		usb0:usb20@11200000 {
			compatible = "mediatek,mt6735-usb20";
			cell-index = <0>;
			reg = <0x11200000 0x10000>,
			      <0x11210000 0x10000>;
			interrupts = <GIC_SPI 72 IRQ_TYPE_LEVEL_LOW>;
			mode = <2>;
			multipoint = <1>;
			num_eps = <16>;
			clocks = <&perisys PERI_USB0>;
			clock-names = "usb0";
			vusb33-supply = <&mt_pmic_vusb33_ldo_reg>;
			iddig_gpio = <0 1>;
			drvvbus_gpio = <83 2>;
		};

		audiosys: audiosys@11220000 {
			compatible = "mediatek,mt6735-audiosys";
			reg = <0x11220000 0x10000>;
			#clock-cells = <1>;
		};

		audio@11220000 {
			compatible = "mediatek,audio";
			reg = <0x11220000 0x10000>;
			interrupts = <GIC_SPI 144 IRQ_TYPE_LEVEL_LOW>;
		};


		audgpio:mt_soc_dl1_pcm@11220000 {
			compatible = "mediatek,mt-soc-dl1-pcm";
			reg = <0x11220000 0x1000>;
			interrupts = <GIC_SPI 144 IRQ_TYPE_LEVEL_LOW>;
			clocks = <&audiosys AUDIO_AFE>,
				<&audiosys AUDIO_I2S>,
				<&audiosys AUDIO_DAC>,
				<&audiosys AUDIO_DAC_PREDIS>,
				<&audiosys AUDIO_ADC>,
				<&audiosys AUDIO_22M>,
				<&audiosys AUDIO_24M>,
				<&audiosys AUDIO_APLL_TUNER>,
				<&audiosys AUDIO_APLL2_TUNER>,
				<&audiosys AUDIO_TML>,
				<&infrasys INFRA_AUDIO>,
				<&topckgen TOP_MUX_AUD1>,
				<&topckgen TOP_MUX_AUD2>,
				<&topckgen TOP_AD_APLL1_CK>,
				<&topckgen TOP_WHPLL_AUDIO_CK>,
				<&topckgen TOP_MUX_AUDIO>,
				<&topckgen TOP_MUX_AUDINTBUS>,
				<&topckgen TOP_SYSPLL1_D4>,
				<&apmixedsys APMIXED_APLL1>,
				<&apmixedsys APMIXED_APLL2>,
				<&clk26m>;
			clock-names = "aud_afe_clk",
				"aud_i2s_clk",
				"aud_dac_clk",
				"aud_dac_predis_clk",
				"aud_adc_clk",
				"aud_apll22m_clk",
				"aud_apll24m_clk",
				"aud_apll1_tuner_clk",
				"aud_apll2_tuner_clk",
				"aud_tml_clk",
				"aud_infra_clk",
				"aud_mux1_clk",
				"aud_mux2_clk",
				"top_ad_apll1_clk",
				"top_whpll_audio_clk",
				"top_mux_audio",
				"top_mux_audio_int",
				"top_sys_pll1_d4",
				"apmixed_apll1_clk",
				"apmixed_apll2_clk",
				"top_clk26m_clk";
			audclk-gpio = <143 0>;
			audmiso-gpio = <144 0>;
			audmosi-gpio = <145 0>;
			vowclk-gpio = <148 0>;
			extspkamp-gpio = <117 0>;
			i2s1clk-gpio = <80 0>;
			i2s1dat-gpio = <78 0>;
			i2s1mclk-gpio = <9 0>;
			i2s1ws-gpio = <79 0>;
		};


		mfgsys: mfgsys@13000000 {
			compatible = "mediatek,mt6735-mfgsys";
			reg = <0x13000000 0x1000>;
			#clock-cells = <1>;
		};

		g3d_config@13000000 {
			compatible = "mediatek,G3D_CONFIG";
			reg = <0x13000000 0x1000>;
		};

		mali@13040000 {
			compatible = "arm,malit720", "arm,mali-t72x", "arm,malit7xx", "arm,mali-midgard";
			reg = <0x13040000 0x4000>;
			interrupts = <GIC_SPI 212 IRQ_TYPE_LEVEL_LOW>,
				<GIC_SPI 211 IRQ_TYPE_LEVEL_LOW>,
				<GIC_SPI 210 IRQ_TYPE_LEVEL_LOW>;
			interrupt-names = "JOB", "MMU", "GPU";
			clock-frequency = <450000000>;
			clocks = <&mfgsys MFG_BG3D>,
				<&mmsys MM_DISP0_SMI_COMMON>,
				<&scpsys SCP_SYS_MFG>,
				<&scpsys SCP_SYS_DIS>;
			clock-names = "mfg-main", "mfg-smi-common", "mtcmos-mfg", "mtcmos-display";
		};

		mmsys: mmsys@14000000 {
			compatible = "mediatek,mt6735-mmsys";
			reg = <0x14000000 0x1000>;
			#clock-cells = <1>;
		};

		mmsys_config@14000000 {
			compatible = "mediatek,mmsys_config";
			reg = <0x14000000 0x1000>;
			interrupts = <GIC_SPI 205 IRQ_TYPE_LEVEL_LOW>;
			clocks = <&mmsys MM_DISP0_CAM_MDP>;
			clock-names = "CAM_MDP";
		};

		mdp_rdma@14001000 {
			compatible = "mediatek,mdp_rdma";
			reg = <0x14001000 0x1000>;
			interrupts = <GIC_SPI 187 IRQ_TYPE_LEVEL_LOW>;
			clocks = <&mmsys MM_DISP0_MDP_RDMA>;
			clock-names = "MDP_RDMA";
		};

		mdp_rsz0@14002000 {
			compatible = "mediatek,mdp_rsz0";
			reg = <0x14002000 0x1000>;
			interrupts = <GIC_SPI 188 IRQ_TYPE_LEVEL_LOW>;
			clocks = <&mmsys MM_DISP0_MDP_RSZ0>;
			clock-names = "MDP_RSZ0";
		};

		mdp_rsz1@14003000 {
			compatible = "mediatek,mdp_rsz1";
			reg = <0x14003000 0x1000>;
			interrupts = <GIC_SPI 189 IRQ_TYPE_LEVEL_LOW>;
			clocks = <&mmsys MM_DISP0_MDP_RSZ1>;
			clock-names = "MDP_RSZ1";
		};

		mdp_wdma@14004000 {
			compatible = "mediatek,mdp_wdma";
			reg = <0x14004000 0x1000>;
			interrupts = <GIC_SPI 191 IRQ_TYPE_LEVEL_LOW>;
			clocks = <&mmsys MM_DISP0_MDP_WDMA>;
			clock-names = "MDP_WDMA";
		};

		mdp_wrot@14005000 {
			compatible = "mediatek,mdp_wrot";
			reg = <0x14005000 0x1000>;
			interrupts = <GIC_SPI 192 IRQ_TYPE_LEVEL_LOW>;
			clocks = <&mmsys MM_DISP0_MDP_WROT>;
			clock-names = "MDP_WROT";
		};

		mdp_tdshp@14006000 {
			compatible = "mediatek,mdp_tdshp";
			reg = <0x14006000 0x1000>;
			interrupts = <GIC_SPI 190 IRQ_TYPE_LEVEL_LOW>;
			clocks = <&mmsys MM_DISP0_MDP_TDSHP>;
			clock-names = "MDP_TDSHP";
		};

		dpi@14012000 {
			compatible = "mediatek,mt6735-dpi";
			reg = <0x14012000 0x1000>;
			interrupts = <GIC_SPI 204 IRQ_TYPE_LEVEL_LOW>;
		};

		dispsys: dispsys@14007000 {
			compatible = "mediatek,mt6735-dispsys";

			reg = <0x14007000 0x1000>,  /*DISP_OVL0      */
			      <0 0>,		    /*DISP_OVL1      */
			      <0x14008000 0x1000>,  /*DISP_RDMA0     */
			      <0x14009000 0x1000>,  /*DISP_RDMA1     */
			      <0x1400A000 0x1000>,  /*DISP_WDMA0     */
			      <0x1400B000 0x1000>,  /*DISP_COLOR     */
			      <0x1400C000 0x1000>,  /*DISP_CCORR     */
			      <0x1400D000 0x1000>,  /*DISP_AAL       */
			      <0x1400E000 0x1000>,  /*DISP_GAMMA     */
			      <0x1400F000 0x1000>,  /*DISP_DITHER    */
			      <0 0>,		    /*DISP_UFOE      */
			      <0x1100E000 0x1000>,  /*DISP_PWM       */
			      <0 0>,		    /*DISP_WDMA1     */
			      <0x14014000 0x1000>,  /*DISP_MUTEX     */
			      <0x14011000 0x1000>,  /*DISP_DSI0      */
			      <0x14012000 0x1000>,  /*DISP_DPI0      */
			      <0x14000000 0x1000>,  /*DISP_CONFIG    */
			      <0x14015000 0x1000>,  /*DISP_SMI_LARB0 */
			      <0x14016000 0x1000>,  /*DISP_SMI_COMMOM*/
			      <0x14017000 0x1000>,  /*MIPITX0,real chip would use this:<0x14017000 0x1000>;*/
			      <0x10206000 0x1000>,  /*DISP_CONFIG2*/
			      <0x10210000 0x1000>,  /*DISP_CONFIG3*/
			      <0x10211A70 0x000C>,  /*DISP_DPI_IO_DRIVING1 */
			      <0x10211974 0x000C>,  /*DISP_DPI_IO_DRIVING2 */
			      <0x10211B70 0x000C>,  /*DISP_DPI_IO_DRIVING3 */
			      <0x10206044 0x000C>,  /*DISP_DPI_EFUSE */
			      <0x10206514 0x000C>,  /*DISP_DPI_EFUSE_PERMISSION */
			      <0x10206558 0x000C>,  /*DISP_DPI_EFUSE_KEY */
			      <0x102100A0 0x1000>,  /*DISP_TVDPLL_CFG6 */
			      <0x10209270 0x1000>,  /*DISP_TVDPLL_CON0 */
			      <0x10209274 0x1000>,  /*DISP_TVDPLL_CON1 */
			      <0 0>,		    /*DISP_OD      */
			      <0x10209000 0x1000>;		    /*DISP_VENCPLL      */

			interrupts = <GIC_SPI 193 IRQ_TYPE_LEVEL_LOW>, /*DISP_OVL0 */
				     <GIC_SPI 0 IRQ_TYPE_LEVEL_LOW>,   /*DISP_OVL1 */
				     <GIC_SPI 194 IRQ_TYPE_LEVEL_LOW>, /*DISP_RDMA0 */
				     <GIC_SPI 195 IRQ_TYPE_LEVEL_LOW>, /*DISP_RDMA1 */
				     <GIC_SPI 196 IRQ_TYPE_LEVEL_LOW>, /*DISP_WDMA0 */
				     <GIC_SPI 197 IRQ_TYPE_LEVEL_LOW>, /*DISP_COLOR */
				     <GIC_SPI 198 IRQ_TYPE_LEVEL_LOW>, /*DISP_CCORR */
				     <GIC_SPI 199 IRQ_TYPE_LEVEL_LOW>, /*DISP_AAL */
				     <GIC_SPI 200 IRQ_TYPE_LEVEL_LOW>, /*DISP_GAMMA */
				     <GIC_SPI 201 IRQ_TYPE_LEVEL_LOW>, /*DISP_DITHER */
				     <GIC_SPI 0 IRQ_TYPE_LEVEL_LOW>,   /*DISP_UFOE */
				     <GIC_SPI 117 IRQ_TYPE_LEVEL_LOW>, /*DISP_PWM */
				     <GIC_SPI 0 IRQ_TYPE_LEVEL_LOW>,   /*DISP_WDMA1 */
				     <GIC_SPI 186 IRQ_TYPE_LEVEL_LOW>, /*DISP_MUTEX */
				     <GIC_SPI 203 IRQ_TYPE_LEVEL_LOW>, /*DISP_DSI0 */
				     <GIC_SPI 204 IRQ_TYPE_LEVEL_LOW>, /*DISP_DPI0 */
				     <GIC_SPI 205 IRQ_TYPE_LEVEL_LOW>, /*DISP_CONFIG, 0 means no IRQ*/
				     <GIC_SPI 176 IRQ_TYPE_LEVEL_LOW>, /*DISP_SMI_LARB0 */
				     <GIC_SPI 0 IRQ_TYPE_LEVEL_LOW>,   /*DISP_SMI_COMMOM*/
				     <GIC_SPI 0 IRQ_TYPE_LEVEL_LOW>,   /*MIPITX0 */
				     <GIC_SPI 0 IRQ_TYPE_LEVEL_LOW>,   /*DISP_CONFIG2*/
				     <GIC_SPI 0 IRQ_TYPE_LEVEL_LOW>,   /*DISP_CONFIG3*/
				     <GIC_SPI 0 IRQ_TYPE_LEVEL_LOW>,   /*DISP_DPI_IO_DRIVING */
				     <GIC_SPI 0 IRQ_TYPE_LEVEL_LOW>,   /*DISP_TVDPLL_CFG6 */
				     <GIC_SPI 0 IRQ_TYPE_LEVEL_LOW>,   /*DISP_TVDPLL_CON0 */
				     <GIC_SPI 0 IRQ_TYPE_LEVEL_LOW>,   /*DISP_TVDPLL_CON1 */
				     <GIC_SPI 0 IRQ_TYPE_LEVEL_LOW>,   /*DISP_OD      */
				     <GIC_SPI 0 IRQ_TYPE_LEVEL_LOW>;   /*DISP_VENCPLL      */

			clocks = <&mmsys MM_DISP0_SMI_COMMON>,
				 <&mmsys MM_DISP0_SMI_LARB0>,
				 <&mmsys MM_DISP0_DISP_OVL0>,
				 <&mmsys MM_DISP0_DISP_RDMA0>,
				 <&mmsys MM_DISP0_DISP_RDMA1>,
				 <&mmsys MM_DISP0_DISP_WDMA0>,
				 <&mmsys MM_DISP0_DISP_COLOR>,
				 <&mmsys MM_DISP0_DISP_CCORR>,
				 <&mmsys MM_DISP0_DISP_AAL>,
				 <&mmsys MM_DISP0_DISP_GAMMA>,
				 <&mmsys MM_DISP0_DISP_DITHER>,
				 <&mmsys MM_DISP1_DSI_ENGINE>,
				 <&mmsys MM_DISP1_DSI_DIGITAL>,
				 <&mmsys MM_DISP1_DPI_ENGINE>,
				 <&mmsys MM_DISP1_DPI_PIXEL>,
				 <&perisys PERI_DISP_PWM>,
				 <&topckgen TOP_MUX_DPI0>,
				 <&apmixedsys APMIXED_TVDPLL>,
				 <&topckgen TOP_TVDPLL_CK>,
				 <&topckgen TOP_TVDPLL_D2>,
				 <&topckgen TOP_TVDPLL_D4>,
				 <&topckgen TOP_DPI_CK>,
				 <&topckgen TOP_MUX_DISPPWM>,
				 <&topckgen TOP_UNIVPLL2_D4>,
				 <&topckgen TOP_SYSPLL4_D2_D8>,
				 <&topckgen TOP_AD_SYS_26M_CK>,
				 <&scpsys SCP_SYS_DIS>;

			clock-names = "DISP0_SMI_COMMON",
				      "DISP0_SMI_LARB0",
				      "DISP0_DISP_OVL0",
				      "DISP0_DISP_RDMA0",
				      "DISP0_DISP_RDMA1",
				      "DISP0_DISP_WDMA0",
				      "DISP0_DISP_COLOR",
				      "DISP0_DISP_CCORR",
				      "DISP0_DISP_AAL",
				      "DISP0_DISP_GAMMA",
				      "DISP0_DISP_DITHER",
				      "DISP1_DSI_ENGINE",
				      "DISP1_DSI_DIGITAL",
				      "DISP1_DPI_ENGINE",
				      "DISP1_DPI_PIXEL",
				      "DISP_PWM",
				      "MUX_DPI0",
				      "TVDPLL",
				      "TVDPLL_CK",
				      "TVDPLL_D2",
				      "TVDPLL_D4",
				      "DPI_CK",
				      "MUX_DISPPWM",
				      "UNIVPLL2_D4",
				      "SYSPLL4_D2_D8",
				      "AD_SYS_26M_CK",
				      "DISP_MTCMOS_CLK";
		};

		mhl:mhl@0 {
			compatible = "mediatek,extd_dev";
		};

		lcm_mode: lcm_mode {
			compatible = "mediatek,lcm_mode";
		};

		smi_larb0@14015000 {
			compatible = "mediatek,smi_larb0";
			reg = <0x14015000 0x1000>;
		};

		smi_common@14016000 {
			compatible = "mediatek,smi_common";
			reg = <0x14016000 0x1000>,  /* SMI_COMMON_EXT */
				<0x14015000 0x1000>,  /* LARB 0 */
				<0x16010000 0x1000>,  /* LARB 1 */
				<0x15001000 0x1000>,  /* LARB 2 */
				<0x17001000 0x1000>;  /* LARB 3 */

			clocks = <&mmsys MM_DISP0_SMI_COMMON>,
				<&mmsys MM_DISP0_SMI_LARB0>,
				<&imgsys IMG_IMAGE_LARB2_SMI>,
				<&vdecsys VDEC0_VDEC>,
				<&vdecsys VDEC1_LARB>,
				<&vencsys VENC_LARB>,
				<&vencsys VENC_VENC>,
				<&scpsys SCP_SYS_VEN>,
				<&scpsys SCP_SYS_VDE>,
				<&scpsys SCP_SYS_ISP>,
				<&scpsys SCP_SYS_DIS>;

			clock-names = "smi-common", "smi-larb0", "img-larb2", "vdec0-vdec",
			"vdec1-larb", "venc-larb", "venc-venc", "mtcmos-ven", "mtcmos-vde",
			"mtcmos-isp", "mtcmos-dis";
		};

		met_smi: met_smi@14016000 {
			compatible = "mediatek,met_smi";
			reg = <0x14016000 0x1000>,  /* SMI_COMMON_EXT */
			    <0x14015000 0x1000>,  /* LARB 0 */
			    <0x16010000 0x1000>,  /* LARB 1 */
			    <0x15001000 0x1000>,  /* LARB 2 */
			    <0x17001000 0x1000>;  /* LARB 3 */

			clocks = <&mmsys MM_DISP0_SMI_COMMON>,
			       <&mmsys MM_DISP0_SMI_LARB0>,
			       <&imgsys IMG_IMAGE_LARB2_SMI>,
			       <&vdecsys VDEC0_VDEC>,
			       <&vdecsys VDEC1_LARB>,
			       <&vencsys VENC_LARB>,
			       <&vencsys VENC_VENC>;

			clock-names = "smi-common",
				"smi-larb0",
				"img-larb2",
				"vdec0-vdec",
				"vdec1-larb",
				"venc-larb",
				"venc-venc";
		};

		imgsys: imgsys@15000000 {
			compatible = "mediatek,mt6735-imgsys";
			reg = <0x15000000 0x1000>;
			#clock-cells = <1>;
		};

		ispsys@15000000 {
			compatible = "mediatek,mt6735-ispsys";
			reg = <0x15004000 0x9000>,  /*ISP_ADDR      */
				<0x1500d000 0x1000>,  /*INNER_ISP_ADDR      */
				<0x15000000 0x10000>,  /*IMGSYS_CONFIG_ADDR      */
				<0x10215000 0x3000>,  /*MIPI_ANA_ADDR      */
				<0x10211000 0x1000>;  /*GPIO_ADDR      */

			interrupts = <GIC_SPI 183 IRQ_TYPE_LEVEL_LOW>, /* CAM0 */
				<GIC_SPI 184 IRQ_TYPE_LEVEL_LOW>, /* CAM1 */
				<GIC_SPI 185 IRQ_TYPE_LEVEL_LOW>, /* CAM2 */
				<GIC_SPI 206 IRQ_TYPE_LEVEL_LOW>, /* CAMSV0 */
				<GIC_SPI 207 IRQ_TYPE_LEVEL_LOW>; /* CAMSV1 */

			clocks = <&scpsys SCP_SYS_DIS>,
				<&scpsys SCP_SYS_ISP>,
				<&mmsys MM_DISP0_SMI_COMMON>,
				<&imgsys IMG_IMAGE_CAM_SMI>,
				<&imgsys IMG_IMAGE_CAM_CAM>,
				<&imgsys IMG_IMAGE_SEN_TG>,
				<&imgsys IMG_IMAGE_SEN_CAM>,
				<&imgsys IMG_IMAGE_CAM_SV>,
				<&imgsys IMG_IMAGE_LARB2_SMI>;

			clock-names = "CG_SCP_SYS_DIS",
				"CG_SCP_SYS_ISP",
				"CG_DISP0_SMI_COMMON",
				"CG_IMAGE_CAM_SMI",
				"CG_IMAGE_CAM_CAM",
				"CG_IMAGE_SEN_TG",
				"CG_IMAGE_SEN_CAM",
				"CG_IMAGE_CAM_SV",
				"CG_IMAGE_LARB2_SMI";
		};


		smi_larb2@15001000 {
			compatible = "mediatek,smi_larb2";
			reg = <0x15001000 0x1000>;
			interrupts = <GIC_SPI 178 IRQ_TYPE_LEVEL_LOW>;
		};

		kd_camera_hw1:kd_camera_hw1@15008000 {
			compatible = "mediatek,camera_hw";
			reg = <0x15008000 0x1000>;  /* SENINF_ADDR */
			vcama-supply = <&mt_pmic_vcama_ldo_reg>;
			vcamd-supply = <&mt_pmic_vcamd_ldo_reg>;
			vcamaf-supply = <&mt_pmic_vcam_af_ldo_reg>;
			vcamio-supply = <&mt_pmic_vcam_io_ldo_reg>;
			/* Camera Common Clock Framework (CCF) */
			clocks = <&topckgen TOP_MUX_CAMTG>,
			<&topckgen TOP_UNIVPLL_D26>,
			<&topckgen TOP_UNIVPLL2_D2>;
			clock-names = "TOP_CAMTG_SEL","TOP_UNIVPLL_D26","TOP_UNIVPLL2_D2";
		};

		kd_camera_hw2:kd_camera_hw2@15008000 {
			compatible = "mediatek,camera_hw2";
			reg = <0x15008000 0x1000>;  /* SENINF_ADDR */
		};

		fdvt@1500b000 {
			compatible = "mediatek,fdvt";
			reg = <0x1500b000 0x1000>;
			interrupts = <GIC_SPI 208 IRQ_TYPE_LEVEL_LOW>;
			clocks = <&scpsys SCP_SYS_DIS>,
				 <&scpsys SCP_SYS_ISP>,
				 <&mmsys MM_DISP0_SMI_COMMON>,
				 <&imgsys IMG_IMAGE_FD>;

			clock-names = "FD-SCP_SYS_DIS",
						"FD-SCP_SYS_ISP",
						"FD-MM_DISP0_SMI_COMMON",
						"FD-IMG_IMAGE_FD";
		};

		vdecsys: vdecsys@16000000 {
			compatible = "mediatek,mt6735-vdecsys";
			reg = <0x16000000 0x1000>;
			interrupts = <GIC_SPI 179 IRQ_TYPE_LEVEL_LOW>;
			#clock-cells = <1>;
		};

		c2k_sdio@0 {
			compatible = "mediatek,mt6735-c2k_sdio";
			interrupts = <GIC_SPI 230 IRQ_TYPE_LEVEL_LOW>;
		};

		vdec_gcon: vdec_gcon@16000000 {
			compatible = "mediatek,mt6735-vdec_gcon";
			reg = <0x16000000 0x1000>;
			interrupts = <GIC_SPI 179 IRQ_TYPE_LEVEL_LOW>;
			clocks =
			<&mmsys MM_DISP0_SMI_COMMON>,
			<&vdecsys VDEC0_VDEC>,
			<&vdecsys VDEC1_LARB>,
			<&vencsys VENC_VENC>,
			<&vencsys VENC_LARB>,
			<&topckgen TOP_MUX_VDEC>,
			<&topckgen TOP_SYSPLL1_D2>,
			<&topckgen TOP_SYSPLL1_D4>,
			<&scpsys SCP_SYS_VDE>,
			<&scpsys SCP_SYS_VEN>,
			<&scpsys SCP_SYS_DIS>;
			clock-names =
			"MT_CG_DISP0_SMI_COMMON",
			"MT_CG_VDEC0_VDEC",
			"MT_CG_VDEC1_LARB",
			"MT_CG_VENC_VENC",
			"MT_CG_VENC_LARB",
			"MT_CG_TOP_MUX_VDEC",
			"MT_CG_TOP_SYSPLL1_D2",
			"MT_CG_TOP_SYSPLL1_D4",
			"MT_SCP_SYS_VDE",
			"MT_SCP_SYS_VEN",
			"MT_SCP_SYS_DIS";
		};

		smi_larb1@16010000 {
			compatible = "mediatek,smi_larb1";
			reg = <0x16010000 0x1000>;
			interrupts = <GIC_SPI 177 IRQ_TYPE_LEVEL_LOW>;
		};

		vdec: vdec@16020000 {
			compatible = "mediatek,mt6735-vdec";
			reg = <0x16020000 0x10000>;
			interrupts = <GIC_SPI 179 IRQ_TYPE_LEVEL_LOW>;
		};

		vencsys: vencsys@17000000 {
			compatible = "mediatek,mt6735-vencsys";
			reg = <0x17000000 0x1000>;
			interrupts = <GIC_SPI 180 IRQ_TYPE_LEVEL_LOW>;
			#clock-cells = <1>;
		};

		venc_gcon: venc_gcon@17000000 {
			compatible = "mediatek,mt6735-venc_gcon";
			reg = <0x17000000 0x1000>;
			interrupts = <GIC_SPI 180 IRQ_TYPE_LEVEL_LOW>;
		};

		smi_larb3@17001000 {
			compatible = "mediatek,smi_larb3";
			reg = <0x17001000 0x1000>;
			interrupts = <GIC_SPI 202 IRQ_TYPE_LEVEL_LOW>;
		};

		venc: venc@17002000 {
			compatible = "mediatek,mt6735-venc";
			reg = <0x17002000 0x1000>;
			interrupts = <GIC_SPI 180 IRQ_TYPE_LEVEL_LOW>;
		};

		jpgenc@17003000 {
			compatible = "mediatek,jpgenc";
			reg = <0x17003000 0x1000>;
			interrupts = <GIC_SPI 181 IRQ_TYPE_LEVEL_LOW>;
			clocks = <&scpsys SCP_SYS_DIS>,
				<&mmsys MM_DISP0_SMI_COMMON>,
				<&scpsys SCP_SYS_VEN>,
				<&vencsys VENC_LARB>,
				<&vencsys VENC_JPGENC>;

			clock-names = "disp-mtcmos",
				"disp-smi",
				"venc-mtcmos",
				"venc-larb",
				"venc-jpgenc";
		};

		jpgdec@17004000 {
			compatible = "mediatek,jpgdec";
			reg = <0x17004000 0x1000>;
			interrupts = <GIC_SPI 209 IRQ_TYPE_LEVEL_LOW>;
			clocks = <&scpsys SCP_SYS_DIS>,
				<&mmsys MM_DISP0_SMI_COMMON>,
				<&scpsys SCP_SYS_VEN>,
				<&vencsys VENC_LARB>,
				<&vencsys VENC_JPGDEC>;

			clock-names = "disp-mtcmos",
				"disp-smi",
				"venc-mtcmos",
				"venc-larb",
				"venc-jpgdec";
		};

		consys:consys@18070000 {
			compatible = "mediatek,mt6735-consys";
			reg = <0x18070000 0x0200>,  /*CONN_MCU_CONFIG_BASE      */
			      <0x10212000 0x0100>,  /*AP_RGU_BASE               */
			      <0x10000000 0x2000>,  /*TOPCKGEN_BASE             */
			      <0x10006000 0x1000>;  /*SPM_BASE                  */
			interrupts = <GIC_SPI 227 IRQ_TYPE_LEVEL_LOW>,  /* BGF_EINT */
						 <GIC_SPI 225 IRQ_TYPE_LEVEL_LOW>;  /* WDT_EINT */
			clocks = <&scpsys SCP_SYS_CONN>,<&infrasys INFRA_CONNMCU_BUS>;
			clock-names = "conn","bus";
			vcn18-supply = <&mt_pmic_vcn18_ldo_reg>;
			vcn28-supply = <&mt_pmic_vcn28_ldo_reg>;
			vcn33_bt-supply = <&mt_pmic_vcn33_bt_ldo_reg>;
			vcn33_wifi-supply = <&mt_pmic_vcn33_wifi_ldo_reg>;
		};

		wifi@180F0000 {
			compatible = "mediatek,wifi";
			reg = <0x180F0000 0x005c>;
			interrupts = <GIC_SPI 226 IRQ_TYPE_LEVEL_LOW>;
			clocks = <&perisys PERI_APDMA>;
			clock-names = "wifi-dma";
		};

		mdc2k@3a00b01c {
			compatible = "mediatek,mdc2k";
			reg =	<0x3a00b01c 0x10>, /*C2K CHIP ID*/
				<0x1021c800 0x300>, /*MD1 PCCIF*/
				<0x1021d800 0x300>; /*MD3 PCCIF*/
			interrupts = <GIC_SPI 229 IRQ_TYPE_EDGE_FALLING>; /*WDT*/
			clocks = <&scpsys SCP_SYS_MD2>;
			clock-names = "scp-sys-md2-main";
		};

		mtkfb:mtkfb@7e000000 {
			compatible = "mediatek,mtkfb";
			reg = <0x7e000000 0x1000000>;
		};

		mt_soc_ul1_pcm{
			compatible = "mediatek,mt_soc_pcm_capture";
		};

		mt_soc_voice_md1{
			compatible = "mediatek,mt_soc_pcm_voice_md1";
		};

		mt_soc_hdmi_pcm{
			compatible = "mediatek,mt_soc_pcm_hdmi";
		};

		mt_soc_uldlloopback_pcm{
			compatible = "mediatek,mt_soc_pcm_uldlloopback";
		};

		mt_soc_i2s0_pcm{
			compatible = "mediatek,mt_soc_pcm_dl1_i2s0";
		};

		mt_soc_mrgrx_pcm{
			compatible = "mediatek,mt_soc_pcm_mrgrx";
		};

		mt_soc_mrgrx_awb_pcm{
			compatible = "mediatek,mt_soc_pcm_mrgrx_awb";
		};

		mt_soc_fm_i2s_pcm{
			compatible = "mediatek,mt_soc_pcm_fm_i2s";
		};

		mt_soc_fm_i2s_awb_pcm{
			compatible = "mediatek,mt_soc_pcm_fm_i2s_awb";
		};

		mt_soc_i2s0dl1_pcm {
			compatible = "mediatek,mt_soc_pcm_dl1_i2s0Dl1";
		};

		mt_soc_deep_buffer_dl_pcm {
			compatible = "mediatek,mt_soc_pcm_deep_buffer_dl";
		};

		mt_soc_dl1_awb_pcm{
			compatible = "mediatek,mt_soc_pcm_dl1_awb";
		};

		mt_soc_voice_md1_bt{
			compatible = "mediatek,mt_soc_pcm_voice_md1_bt";
		};

		mt_soc_voip_bt_out {
			compatible = "mediatek,mt_soc_pcm_dl1_bt";
		};

		mt_soc_voip_bt_in {
			compatible = "mediatek,mt_soc_pcm_bt_dai";
		};

		mt_soc_tdmrx_pcm {
			compatible = "mediatek,mt_soc_tdm_capture";
		};

		mt_soc_fm_mrgtx_pcm {
			compatible = "mediatek,mt_soc_pcm_fmtx";
		};

		mt_soc_ul2_pcm {
			compatible = "mediatek,mt_soc_pcm_capture2";
		};

		mt_soc_i2s0_awb_pcm {
			compatible = "mediatek,mt_soc_pcm_i2s0_awb";
		};

		mt_soc_voice_md2 {
			compatible = "mediatek,mt_soc_pcm_voice_md2";
		};

		mt_soc_routing_pcm {
			compatible = "mediatek,mt_soc_pcm_routing";
			i2s1clk-gpio = <7 6>;
			i2s1dat-gpio = <5 6>;
			i2s1mclk-gpio = <9 6>;
			i2s1ws-gpio = <6 6>;
		};

		mt_soc_voice_md2_bt {
			compatible = "mediatek,mt_soc_pcm_voice_md2_bt";
		};

		mt_soc_hp_impedance_pcm {
			compatible = "mediatek,Mt_soc_pcm_hp_impedance";
		};

		mt_soc_codec_name {
			compatible = "mediatek,mt_soc_codec_63xx";
		};

		mt_soc_dummy_pcm {
			compatible = "mediatek,mt_soc_pcm_dummy";
		};

		mt_soc_codec_dummy_name {
			compatible = "mediatek,mt_soc_codec_dummy";
		};

		mt_soc_routing_dai_name {
			compatible = "mediatek,mt_soc_dai_routing";
		};

		mt_soc_dai_name {
			compatible = "mediatek,mt_soc_dai_stub";
		};

		mt_soc_offload_gdma {
			compatible = "mediatek,mt_soc_pcm_offload_gdma";
		};

		mt_soc_dl2_pcm {
			compatible = "mediatek,mt_soc_pcm_dl2";
		};

		touch: touch {
			compatible = "mediatek,mt6735-touch";
			vtouch-supply = <&mt_pmic_vgp1_ldo_reg>;
		};

		accdet: accdet {
			compatible = "mediatek,mt6735-accdet";
		};

		nfc:nfc {
			compatible = "mediatek,nfc-gpio-v2";
			gpio-ven = <4>;
			gpio-rst = <3>;
			gpio-eint = <1>;
			gpio-irq = <2>;
		};

		gps {
			compatible = "mediatek,gps";
		};

		ssw:simswitch{
			compatible = "mediatek,sim_switch";
			pinctrl-names =	"default",
					"hot_plug_mode1",
					"hot_plug_mode2",
					"two_sims_bound_to_md1",
					"sim1_md3_sim2_md1";
			pinctrl-0 = <&ssw_default>;
			pinctrl-1 = <&ssw_hot_plug_mode1>;
			pinctrl-2 = <&ssw_hot_plug_mode2>;
			pinctrl-3 = <&ssw_two_sims_bound_to_md1>;
			pinctrl-4 = <&ssw_sim1_md3_sim2_md1>;
		};

		ccci_off {
			compatible = "mediatek,ccci_off";
			clocks = <&scpsys SCP_SYS_MD1>;
			clock-names = "scp-sys-md1-main";
		};

		pmu {
			compatible = "arm,cortex-a7-pmu";
			interrupts = <GIC_SPI 8 IRQ_TYPE_LEVEL_LOW>,
				<GIC_SPI 9 IRQ_TYPE_LEVEL_LOW>,
				<GIC_SPI 10 IRQ_TYPE_LEVEL_LOW>,
				<GIC_SPI 11 IRQ_TYPE_LEVEL_LOW>;
			interrupt-affinity = <&cpu0>,
					     <&cpu1>,
					     <&cpu2>,
					     <&cpu3>;
		};

		timer {
			compatible = "arm,armv8-timer";
			interrupts = <GIC_PPI 13 IRQ_TYPE_LEVEL_LOW>, /*Secure Physical Timer Event*/
				<GIC_PPI 14 IRQ_TYPE_LEVEL_LOW>, /*Non-Secure Physical Timer Event*/
				<GIC_PPI 11 IRQ_TYPE_LEVEL_LOW>, /*Virtual Timer Event*/
				<GIC_PPI 10 IRQ_TYPE_LEVEL_LOW>; /*Hypervisor Timer Event*/
				clock-frequency = <13000000>;
		};

		mt_pmic_regulator {
			compatible = "mediatek,mt_pmic";
			/*reg = <0x01>*/
			buck_regulators {
			compatible = "mediatek,mt_pmic_buck_regulators";
				mt_pmic_vpa_buck_reg: buck_vpa {
					regulator-name = "vpa";
					regulator-min-microvolt = <500000>;
					regulator-max-microvolt = <3650000>;
					regulator-ramp-delay = <50000>;
					regulator-enable-ramp-delay = <180>;
				};
				mt_pmic_vproc_buck_reg: buck_vproc {
					regulator-name = "vproc";
					regulator-min-microvolt = <600000>;
					regulator-max-microvolt = <1393750>;
					regulator-ramp-delay = <6250>;
					regulator-enable-ramp-delay = <180>;
					regulator-always-on;
					regulator-boot-on;
				};
				mt_pmic_vcore1_buck_reg: buck_vcore1 {
					regulator-name = "vcore1";
					regulator-min-microvolt = <600000>;
					regulator-max-microvolt = <1393750>;
					regulator-ramp-delay = <6250>;
					regulator-enable-ramp-delay = <180>;
					regulator-always-on;
					regulator-boot-on;
				};
				mt_pmic_vsys22_buck_reg: buck_vsys22 {
					regulator-name = "vsys22";
					regulator-min-microvolt = <1200000>;
					regulator-max-microvolt = <1993750>;
					regulator-ramp-delay = <6250>;
					regulator-enable-ramp-delay = <180>;
					regulator-always-on;
					regulator-boot-on;
				};
				mt_pmic_vlte_buck_reg: buck_vlte {
					regulator-name = "vlte";
					regulator-min-microvolt = <600000>;
					regulator-max-microvolt = <1393750>;
					regulator-ramp-delay = <6250>;
					regulator-enable-ramp-delay = <180>;
					regulator-always-on;
					regulator-boot-on;
				};
			};	/* End of buck_regulators */
			ldo_regulators {
				compatible = "mediatek,mt_pmic_ldo_regulators";
				mt_pmic_vaux18_ldo_reg: ldo_vaux18 {
					regulator-name = "vaux18";
					regulator-min-microvolt = <1800000>;
					regulator-max-microvolt = <1800000>;
					regulator-enable-ramp-delay = <264>;
					regulator-boot-on;
				};
				mt_pmic_vtcxo_0_ldo_reg: ldo_vtcxo_0 {
					regulator-name = "vtcxo_0";
					regulator-min-microvolt = <2800000>;
					regulator-max-microvolt = <2800000>;
					regulator-enable-ramp-delay = <110>;
					regulator-boot-on;
				};
				mt_pmic_vtcxo_1_ldo_reg: ldo_vtcxo_1 {
					regulator-name = "vtcxo_1";
					regulator-min-microvolt = <2800000>;
					regulator-max-microvolt = <2800000>;
					regulator-enable-ramp-delay = <110>;
				};
				mt_pmic_vaud28_ldo_reg: ldo_vaud28 {
					regulator-name = "vaud28";
					regulator-min-microvolt = <2800000>;
					regulator-max-microvolt = <2800000>;
					regulator-enable-ramp-delay = <264>;
					regulator-boot-on;
				};
				mt_pmic_vcn28_ldo_reg: ldo_vcn28 {
					regulator-name = "vcn28";
					regulator-min-microvolt = <2800000>;
					regulator-max-microvolt = <2800000>;
					regulator-enable-ramp-delay = <264>;
				};
				mt_pmic_vcama_ldo_reg: ldo_vcama {
					regulator-name = "vcama";
					regulator-min-microvolt = <1500000>;
					regulator-max-microvolt = <2800000>;
					regulator-enable-ramp-delay = <264>;
				};
				mt_pmic_vcn33_bt_ldo_reg: ldo_vcn33_bt {
					regulator-name = "vcn33_bt";
					regulator-min-microvolt = <3300000>;
					regulator-max-microvolt = <3600000>;
					regulator-enable-ramp-delay = <264>;
				};
				mt_pmic_vcn33_wifi_ldo_reg: ldo_vcn33_wifi {
					regulator-name = "vcn33_wifi";
					regulator-min-microvolt = <3300000>;
					regulator-max-microvolt = <3600000>;
					regulator-enable-ramp-delay = <264>;
				};
				mt_pmic_vusb33_ldo_reg: ldo_vusb33 {
					regulator-name = "vusb33";
					regulator-min-microvolt = <3300000>;
					regulator-max-microvolt = <3300000>;
					regulator-enable-ramp-delay = <264>;
					regulator-boot-on;
				};
				mt_pmic_vefuse_ldo_reg: ldo_vefuse {
					regulator-name = "vefuse";
					regulator-min-microvolt = <1800000>;
					regulator-max-microvolt = <2200000>;
					regulator-enable-ramp-delay = <264>;
				};
				mt_pmic_vsim1_ldo_reg: ldo_vsim1 {
					regulator-name = "vsim1";
					regulator-min-microvolt = <1700000>;
					regulator-max-microvolt = <2100000>;
					regulator-enable-ramp-delay = <264>;
				};
				mt_pmic_vsim2_ldo_reg: ldo_vsim2 {
					regulator-name = "vsim2";
					regulator-min-microvolt = <1700000>;
					regulator-max-microvolt = <2100000>;
					regulator-enable-ramp-delay = <264>;
				};
				mt_pmic_vemc33_ldo_reg: ldo_vemc_3v3 {
					regulator-name = "vemc_3v3";
					regulator-min-microvolt = <1800000>;
					regulator-max-microvolt = <3300000>;
					regulator-enable-ramp-delay = <264>;
					regulator-boot-on;
				};
				mt_pmic_vmch_ldo_reg: ldo_vmch {
					regulator-name = "vmch";
					regulator-min-microvolt = <2900000>;
					regulator-max-microvolt = <3300000>;
					regulator-enable-ramp-delay = <44>;
				};
				mt_pmic_vtref_ldo_reg: ldo_vtref {
					regulator-name = "vtref";
					regulator-min-microvolt = <1800000>;
					regulator-max-microvolt = <1800000>;
					regulator-enable-ramp-delay = <240>;
				};
				mt_pmic_vmc_ldo_reg: ldo_vmc {
					regulator-name = "vmc";
					regulator-min-microvolt = <1800000>;
					regulator-max-microvolt = <3300000>;
					regulator-enable-ramp-delay = <44>;
				};
				mt_pmic_vcam_af_ldo_reg: ldo_vcamaf {
					regulator-name = "vcamaf";
					regulator-min-microvolt = <1200000>;
					regulator-max-microvolt = <3300000>;
					regulator-enable-ramp-delay = <264>;
				};
				mt_pmic_vio28_ldo_reg: ldo_vio28 {
					regulator-name = "vio28";
					regulator-min-microvolt = <2800000>;
					regulator-max-microvolt = <2800000>;
					regulator-enable-ramp-delay = <264>;
					regulator-boot-on;
				};
				mt_pmic_vgp1_ldo_reg: ldo_vgp1 {
					regulator-name = "vgp1";
					regulator-min-microvolt = <1200000>;
					regulator-max-microvolt = <3300000>;
					regulator-enable-ramp-delay = <264>;
				};
				mt_pmic_vibr_ldo_reg: ldo_vibr {
					regulator-name = "vibr";
					regulator-min-microvolt = <1200000>;
					regulator-max-microvolt = <3300000>;
					regulator-enable-ramp-delay = <44>;
				};
				mt_pmic_vcamd_ldo_reg: ldo_vcamd {
					regulator-name = "vcamd";
					regulator-min-microvolt = <900000>;
					regulator-max-microvolt = <1500000>;
					regulator-enable-ramp-delay = <264>;
				};
				mt_pmic_vrf18_0_ldo_reg: ldo_vrf18_0 {
					regulator-name = "vrf18_0";
					regulator-min-microvolt = <1825000>;
					regulator-max-microvolt = <1825000>;
					regulator-enable-ramp-delay = <220>;
				};
				mt_pmic_vrf18_1_ldo_reg: ldo_vrf18_1 {
					regulator-name = "vrf18_1";
					regulator-min-microvolt = <1200000>;
					regulator-max-microvolt = <1825000>;
					regulator-enable-ramp-delay = <220>;
				};
				mt_pmic_vio18_ldo_reg: ldo_vio18 {
					regulator-name = "vio18";
					regulator-min-microvolt = <1800000>;
					regulator-max-microvolt = <1800000>;
					regulator-enable-ramp-delay = <264>;
					regulator-boot-on;
				};
				mt_pmic_vcn18_ldo_reg: ldo_vcn18 {
					regulator-name = "vcn18";
					regulator-min-microvolt = <1800000>;
					regulator-max-microvolt = <1800000>;
					regulator-enable-ramp-delay = <44>;
				};
				mt_pmic_vcam_io_ldo_reg: ldo_vcamio {
					regulator-name = "vcamio";
					regulator-min-microvolt = <1200000>;
					regulator-max-microvolt = <1800000>;
					regulator-enable-ramp-delay = <220>;
				};
				mt_pmic_vsram_ldo_reg: ldo_vsram {
					regulator-name = "vsram";
					regulator-min-microvolt = <700000>;
					regulator-max-microvolt = <1493750>;
					regulator-enable-ramp-delay = <220>;
					regulator-ramp-delay = <6250>;
					regulator-boot-on;
				};
				mt_pmic_vm_ldo_reg: ldo_vm {
					regulator-name = "vm";
					regulator-min-microvolt = <1240000>;
					regulator-max-microvolt = <1540000>;
					regulator-enable-ramp-delay = <264>;
					regulator-boot-on;
				};
			};/* End of ldo_regulators */
			regulators_supply {
				compatible = "mediatek,mt_pmic_regulator_supply";
				vaux18-supply = <&mt_pmic_vaux18_ldo_reg>;
				vtcxo_0-supply = <&mt_pmic_vtcxo_0_ldo_reg>;
				vtcxo_1-supply = <&mt_pmic_vtcxo_1_ldo_reg>;
				vaud28-supply = <&mt_pmic_vaud28_ldo_reg>;
				vefuse-supply = <&mt_pmic_vefuse_ldo_reg>;
				vsim1-supply = <&mt_pmic_vsim1_ldo_reg>;
				vsim2-supply = <&mt_pmic_vsim2_ldo_reg>;
				vemc_3v3-supply = <&mt_pmic_vemc33_ldo_reg>;
				vmch-supply = <&mt_pmic_vmch_ldo_reg>;
				vtref-supply = <&mt_pmic_vtref_ldo_reg>;
				vmc-supply = <&mt_pmic_vmc_ldo_reg>;
				vio28-supply = <&mt_pmic_vio28_ldo_reg>;
				vibr-supply = <&mt_pmic_vibr_ldo_reg>;
				vrf18_0-supply = <&mt_pmic_vrf18_0_ldo_reg>;
				vrf18_1-supply = <&mt_pmic_vrf18_1_ldo_reg>;
				vio18-supply = <&mt_pmic_vio18_ldo_reg>;
				vsram-supply = <&mt_pmic_vsram_ldo_reg>;
				vm-supply = <&mt_pmic_vm_ldo_reg>;
			};/* End of regulators_supply */
		};/* End of mt_pmic_regulator */

		btcvsd@10000000 {
			compatible = "mediatek,audio_bt_cvsd";
			offset = <0x700 0x800 0xfd0 0xfd4 0xfd8>;
			/*INFRA MISC, conn_bt_cvsd_mask, cvsd_mcu_read, write, packet_indicator*/
			reg = <0x10000000 0x1000>, /*AUDIO_INFRA_BASE_PHYSICAL*/
				<0x18000000 0x10000>, /*PKV_PHYSICAL_BASE*/
				<0x18080000 0x8000>; /*SRAM_BANK2*/
			interrupts = <GIC_SPI 228 IRQ_TYPE_LEVEL_LOW>;
		};

		bat_meter: bat_meter{
			compatible = "mediatek,bat_meter";
		};

		BAT_NOTIFY {
			compatible = "mediatek,bat_notify";
		};

		bat_comm: bat_comm {
			compatible = "mediatek,battery";
		};
		dsi_te: dsi_te {
			compatible = "mediatek, DSI_TE_1-eint";
			status = "disabled";
		};
	};

	vcorefs {
		compatible = "mediatek,mt6735-vcorefs";
		clocks = <&topckgen TOP_MUX_AXI>,
			 <&topckgen TOP_SYSPLL_D5>,
			 <&topckgen TOP_SYSPLL1_D4>;
		clock-names = "mux_axi",
			      "syspll_d5",
			      "syspll1_d4";
	};

	rf_clock_buffer_ctrl:rf_clock_buffer {
		compatible = "mediatek,rf_clock_buffer";
		mediatek,clkbuf-quantity = <4>;
		mediatek,clkbuf-config = <2 1 1 1>;
	};

/* sensor part */
	hwmsensor {
		compatible = "mediatek,hwmsensor";
	};
	gsensor {
		compatible = "mediatek,gsensor";
	};
	alsps:als_ps {
		compatible = "mediatek,als_ps";
	};
	m_acc_pl {
		compatible = "mediatek,m_acc_pl";
	};

	m_alsps_pl {
		compatible = "mediatek,m_alsps_pl";
	};

	m_batch_pl {
		compatible = "mediatek,m_batch_pl";
	};
	batchsensor {
		compatible = "mediatek,batchsensor";
	};
	gyro:gyroscope {
		compatible = "mediatek,gyroscope";
	};
	m_gyro_pl {
		compatible = "mediatek,m_gyro_pl";
	};
	barometer {
		compatible = "mediatek,barometer";
	};
	m_baro_pl {
		compatible = "mediatek,m_baro_pl";
	};
	msensor {
		compatible = "mediatek,msensor";
	};
	m_mag_pl {
		compatible = "mediatek,m_mag_pl";
	};
	orientation {
		compatible = "mediatek,orientation";
	};

	als: als {
		compatible = "mediatek, als-eint";
	};

	audio_switch {
		compatible = "mediatek,audio_switch";
	};

/* sensor end */

	/* dummy nodes for cust_eint */
	gse_1: gse_1 {
		compatible = "mediatek, gse_1-eint";
		status = "disabled";
	};

	ext_buck_oc: ext_buck_oc {
		compatible = "mediatek, ext_buck_oc-eint";
		status = "disabled";
	};

	mt8193ckgen: mt8193ckgen@0 {
		compatible = "mediatek,mt8193-ckgen";
	};

	multibridge {
		compatible = "mediatek,multibridge";
	};

	firmware {
		android {
			compatible = "android,firmware";
			fstab {
				compatible = "android,fstab";
#if !defined(CONFIG_SYSTEM_AS_ROOT) && !defined(CONFIG_MTK_AB_OTA_UPDATER)
				system {
					compatible = "android,system";
					dev = "/dev/block/platform/mtk-msdc.0/11230000.msdc0/by-name/system";
					type = "ext4";
					mnt_flags = "ro";
					#ifndef CONFIG_MTK_DM_VERITY_OFF
					fsmgr_flags = "wait,verify";
					#else
					fsmgr_flags = "wait";
					#endif
				};
#endif
#ifndef CONFIG_MTK_LATE_MOUNT
				vendor {
					compatible = "android,vendor";
					dev = "/dev/block/platform/mtk-msdc.0/11230000.msdc0/by-name/vendor";
					type = "ext4";
					mnt_flags = "ro";
#ifndef CONFIG_MTK_AB_OTA_UPDATER
					#ifndef CONFIG_MTK_DM_VERITY_OFF
					fsmgr_flags = "wait,verify";
					#else
					fsmgr_flags = "wait";
					#endif
#else
					#ifndef CONFIG_MTK_DM_VERITY_OFF
					fsmgr_flags = "wait,slotselect,verify";
					#else
					fsmgr_flags = "wait,slotselect";
					#endif
#endif
				};
#endif
#ifdef CONFIG_TARGET_COPY_OUT_ODM
				odm {
					compatible = "android,odm";
					dev = "/dev/block/platform/mtk-msdc.0/11230000.msdc0/by-name/odm";
					type = "ext4";
					mnt_flags = "ro";
#ifndef CONFIG_MTK_AB_OTA_UPDATER
					fsmgr_flags = "wait";
#else
					fsmgr_flags = "wait,slotselect";
#endif
				};
#endif
			};
		};
	};

	odm: odm{
		compatible = "simple-bus";
		/* reserved for overlay by odm */
	};
};

&mt8193ckgen {
	pinctrl-names = "default", "bus_switch_gpio", "bus_switch_dpi";
	pinctrl-0 = <&mt8193ckgen_pins_default>;
	pinctrl-1 = <&mt8193ckgen_pins_gpio>;
	pinctrl-2 = <&mt8193ckgen_pins_dpi>;
	bus_switch_pin = <&pio 0 0>;
	status = "okay";
};

&pio {
	mt8193ckgen_pins_default: 8193ckgen_default {
	};

	mt8193ckgen_pins_gpio: 8193ckgen_gpio {
		pins_cmd_dat {
			pins = <PINMUX_GPIO0__FUNC_GPIO0>;
			slew-rate = <1>;
			bias-pull-up = <00>;
			output-high;
		};
	};

	mt8193ckgen_pins_dpi: 8193ckgen_dpi {
		pins_cmd_dat {
			pins = <PINMUX_GPIO0__FUNC_DPI_D4>;
		};
	};
};

&eintc {
	pmic@206 {
	compatible = "mediatek, pmic-eint";
	interrupt-parent = <&eintc>;
	interrupts = <206 IRQ_TYPE_LEVEL_HIGH>;
	debounce = <206 1000>;
	};
};

&pio {
	ssw_default:ssw0default {
	};

	ssw_hot_plug_mode1:ssw@1 {

		pins_cmd0_dat {
			pins = <PINMUX_GPIO8__FUNC_MD_EINT1>;
		};

		pins_cmd1_dat {
			pins = <PINMUX_GPIO9__FUNC_MD_EINT2>;
		};
	};

	ssw_hot_plug_mode2:ssw@2 {

		pins_cmd0_dat {
			pins = <PINMUX_GPIO8__FUNC_C2K_UIM0_HOT_PLUG_IN>;
		};

		pins_cmd1_dat {
			pins = <PINMUX_GPIO9__FUNC_MD_EINT2>;
		};
	};

	ssw_two_sims_bound_to_md1:ssw@3 {
		pins_cmd0_dat {
			pins = <PINMUX_GPIO163__FUNC_MD_SIM1_SCLK>;
			slew-rate = <1>;
		};

		pins_cmd1_dat {
			pins = <PINMUX_GPIO164__FUNC_MD_SIM1_SRST>;
			slew-rate = <1>;
		};

		pins_cmd2_dat {
			pins = <PINMUX_GPIO165__FUNC_MD_SIM1_SDAT>;
			slew-rate = <0>;
			bias-pull-up = <00>;

		};

		pins_cmd3_dat {
			pins = <PINMUX_GPIO160__FUNC_MD_SIM2_SCLK>;
			slew-rate = <1>;
		};

		pins_cmd4_dat {
			pins = <PINMUX_GPIO161__FUNC_MD_SIM2_SRST>;
			slew-rate = <1>;
		};

		pins_cmd5_dat {
			pins = <PINMUX_GPIO162__FUNC_MD_SIM2_SDAT>;
			slew-rate = <0>;
			bias-pull-up = <00>;
		};
	};

	ssw_sim1_md3_sim2_md1:ssw@4 {
		pins_cmd0_dat {
			pins = <PINMUX_GPIO163__FUNC_UIM0_CLK>;
		};

		pins_cmd1_dat {
			pins = <PINMUX_GPIO164__FUNC_UIM0_RST>;
		};

		pins_cmd2_dat {
			pins = <PINMUX_GPIO165__FUNC_UIM0_IO>;
		};

		pins_cmd3_dat {
			pins = <PINMUX_GPIO160__FUNC_MD_SIM2_SCLK>;
		};

		pins_cmd4_dat {
			pins = <PINMUX_GPIO161__FUNC_MD_SIM2_SRST>;
		};

		pins_cmd5_dat {
			pins = <PINMUX_GPIO162__FUNC_MD_SIM2_SDAT>;
		};
	};
};

&mdcldma {
	pinctrl-names = "default", "vsram_output_low", "vsram_output_high", "RFIC0_01_mode", "RFIC0_04_mode";

	pinctrl-0 = <&vsram_default>;
	pinctrl-1 = <&vsram_output_low>;
	pinctrl-2 = <&vsram_output_high>;
	pinctrl-3 = <&RFIC0_01_mode>;
	pinctrl-4 = <&RFIC0_04_mode>;
};

&pio {
	vsram_default: vsram0default {
	};

	vsram_output_low: vsram@1 {
		pins_cmd_dat {
			pins = <PINMUX_GPIO140__FUNC_GPIO140>;
			slew-rate = <1>;
			output-low;
		};
	};

	vsram_output_high: vsram@2 {
		pins_cmd_dat {
			pins = <PINMUX_GPIO140__FUNC_GPIO140>;
			slew-rate = <1>;
			output-high;
		};
	};

	RFIC0_01_mode: clockbuf@1{

		pins_cmd0_dat {
			pins = <PINMUX_GPIO110__FUNC_RFIC0_BSI_EN>;
		};

		pins_cmd1_dat {
			pins = <PINMUX_GPIO111__FUNC_RFIC0_BSI_CK>;
		};

		pins_cmd2_dat {
			pins = <PINMUX_GPIO112__FUNC_RFIC0_BSI_D2>;
		};


		pins_cmd3_dat {
			pins = <PINMUX_GPIO113__FUNC_RFIC0_BSI_D1>;
		};

		pins_cmd4_dat {
			pins = <PINMUX_GPIO114__FUNC_RFIC0_BSI_D0>;
		};
	};

	RFIC0_04_mode: clockbuf@2{

		pins_cmd0_dat {
			pins = <PINMUX_GPIO110__FUNC_SPM_BSI_EN>;
		};

		pins_cmd1_dat {
			pins = <PINMUX_GPIO111__FUNC_SPM_BSI_CLK>;
		};

		pins_cmd2_dat {
			pins = <PINMUX_GPIO112__FUNC_SPM_BSI_D2>;
		};

		pins_cmd3_dat {
			pins = <PINMUX_GPIO113__FUNC_SPM_BSI_D1>;
		};

		pins_cmd4_dat {
			pins = <PINMUX_GPIO114__FUNC_SPM_BSI_D0>;
		};

	};
};

&pio {
	/* UART GPIO Settings - Start */

	/* UART0: rx set, rx clear, tx clear, tx clear*/
	uart0_gpio_def_cfg:uart0gpiodefault {

	};
	uart0_rx_set_cfg:uart0_rx_set@gpio74 {
	    pins_cmd_dat {
			pins = <PINMUX_GPIO74__FUNC_URXD0>;
		};
	};
	uart0_rx_clr_cfg:uart0_rx_clear@gpio74  {
	    pins_cmd_dat {
			pins = <PINMUX_GPIO74__FUNC_GPIO74>;
			slew-rate = <1>;
			output-high;
		};
	};
	uart0_tx_set_cfg:uart0_tx_set@gpio75  {
	    pins_cmd_dat {
			pins = <PINMUX_GPIO75__FUNC_UTXD0>;
		};
	};
	uart0_tx_clr_cfg:uart0_tx_clear@gpio75  {
	    pins_cmd_dat {
			pins = <PINMUX_GPIO75__FUNC_GPIO75>;
			slew-rate = <1>;
			output-high;
		};
	};

	/* UART1: rx set, rx clear, tx clear, tx clear*/
	uart1_gpio_def_cfg:uart1gpiodefault {

	};
	uart1_rx_set_cfg:uart1_rx_set@gpio76 {
	    pins_cmd_dat {
			pins = <PINMUX_GPIO76__FUNC_URXD1>;
		};
	};
	uart1_rx_clr_cfg:uart1_rx_clear@gpio76 {
	    pins_cmd_dat {
			pins = <PINMUX_GPIO76__FUNC_GPIO76>;
			slew-rate = <1>;
			output-high;
		};
	};
	uart1_tx_set_cfg:uart1_tx_set@gpio77 {
	    pins_cmd_dat {
			pins = <PINMUX_GPIO77__FUNC_UTXD1>;
		};
	};
	uart1_tx_clr_cfg:uart1_tx_clear@gpio77 {
	    pins_cmd_dat {
			pins = <PINMUX_GPIO77__FUNC_GPIO77>;
			slew-rate = <1>;
			output-high;
		};
	};


	/* UART2: rx set, rx clear, tx clear, tx clear*/
	uart2_gpio_def_cfg:uart2gpiodefault {

	};
	uart2_rx_set_cfg:uart2_rx_set@gpio57 {
	    pins_cmd_dat {
			pins = <PINMUX_GPIO57__FUNC_URXD2>;
		};
	};
	uart2_rx_clr_cfg:uart2_rx_clear@gpio57 {
	    pins_cmd_dat {
			pins = <PINMUX_GPIO57__FUNC_GPIO57>;
			slew-rate = <1>;
			output-high;
		};
	};
	uart2_tx_set_cfg:uart2_tx_set@gpio58 {
	    pins_cmd_dat {
			pins = <PINMUX_GPIO58__FUNC_UTXD2>;
		};
	};
	uart2_tx_clr_cfg:uart2_tx_clear@gpio58 {
	    pins_cmd_dat {
			pins = <PINMUX_GPIO58__FUNC_GPIO58>;
			slew-rate = <1>;
			output-high;
		};
	};


	/* UART3: rx set, rx clear, tx clear, tx clear*/
	uart3_gpio_def_cfg:uart3gpiodefault {

	};
	uart3_rx_set_cfg:uart3_rx_set@gpio59 {
	    pins_cmd_dat {
			pins = <PINMUX_GPIO59__FUNC_URXD3>;
		};
	};
	uart3_rx_clr_cfg:uart3_rx_clear@gpio59 {
	    pins_cmd_dat {
			pins = <PINMUX_GPIO59__FUNC_GPIO59>;
			slew-rate = <1>;
			output-high;
		};
	};
	uart3_tx_set_cfg:uart3_tx_set@gpio60 {
	    pins_cmd_dat {
			pins = <PINMUX_GPIO60__FUNC_UTXD3>;
		};
	};
	uart3_tx_clr_cfg:uart3_tx_clear@gpio60 {
	    pins_cmd_dat {
			pins = <PINMUX_GPIO60__FUNC_GPIO60>;
			slew-rate = <1>;
			output-high;
		};
	};

	/* UART GPIO Settings - End */
};

&pio {
	/* IRTX GPIO Settings -Start */
	/* default: GPIO0, output, high */
	irtx_gpio_default:irtx_gpio_led_def@gpio19 {
	    pins_cmd_dat {
			pins = <PINMUX_GPIO19__FUNC_GPIO19>;
			slew-rate = <1>;
			bias-disable;
			output-high;
			input-schmitt-enable = <0>;
		};
	};

	irtx_gpio_led_set:irtx_gpio_led_set@gpio19 {
	    pins_cmd_dat {
			pins = <PINMUX_GPIO19__FUNC_IRTX_OUT>;
		};
	};
	/* IRTX GPIO Settings -End */
};

#include <trusty.dtsi>
